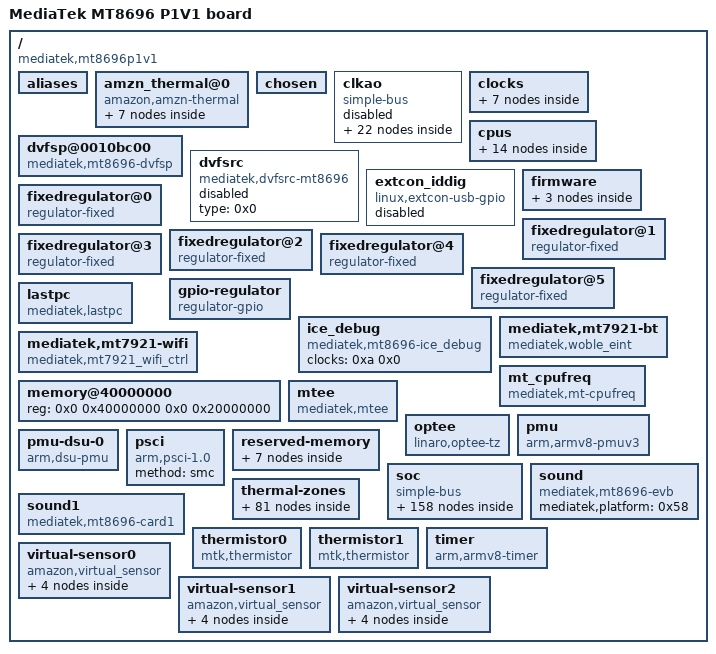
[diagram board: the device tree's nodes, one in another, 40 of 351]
/dts-v1/;

/ {
	#address-cells = <0x2>;
	#size-cells = <0x2>;
	compatible = "mediatek,mt8696p1v1", "mediatek,mt8696";
	interrupt-parent = <0x1>;
	model = "MediaTek MT8696 P1V1 board";

	__symbols__ {
		afe = "/soc/audio-controller@11228000";
		afe32 = "/soc/audio-controller@11220000";
		amzn_thermal = "/amzn_thermal@0";
		android = "/firmware/android";
		apmixedsys = "/soc/syscon@1000c000";
		atf_reserved_mem = "/reserved-memory/atf-reserved-memory@43000000";
		auxadc = "/soc/adc@11001000";
		board_trip10 = "/thermal-zones/top_thermal/trips/trip-point@0";
		board_trip11 = "/thermal-zones/top_thermal/trips/trip-point@1";
		board_trip12 = "/thermal-zones/top_thermal/trips/trip-point@2";
		board_trip_critical1 = "/thermal-zones/top_thermal/trips/trip-point@3";
		bottom_trip10 = "/thermal-zones/bottom_thermal/trips/trip-point@0";
		bottom_trip11 = "/thermal-zones/bottom_thermal/trips/trip-point@1";
		bottom_trip12 = "/thermal-zones/bottom_thermal/trips/trip-point@2";
		bottom_trip_critical1 = "/thermal-zones/bottom_thermal/trips/trip-point@3";
		clk12m = "/clocks/clk12m";
		clk13m = "/clocks/clk13m";
		clk26m = "/clocks/clk26m";
		clk32k = "/clocks/clk32k";
		clk_null = "/clocks/clk_null";
		clkao = "/clkao";
		clki2sin_mclk_i = "/clocks/oscillator@0";
		clksplin_mclk_i = "/clocks/oscillator@1";
		clovelly = "/soc/gpu@13000000";
		clusteroff = "/cpus/idle-states/clusteroff";
		cpu0 = "/cpus/cpu@000";
		cpu1 = "/cpus/cpu@001";
		cpu2 = "/cpus/cpu@002";
		cpu3 = "/cpus/cpu@003";
		cpu_cluster0 = "/amzn_thermal@0/cpu_core_cluster0";
		cpuoff = "/cpus/idle-states/cpuoff";
		cpus = "/cpus";
		disp_adl_ml = "/soc/disp_adl_ml@14013000";
		disp_befifo = "/soc/disp_befifo@1400f000";
		disp_fefifo = "/soc/disp_fefifo@14010000";
		disp_fmt = "/soc/disp_fmt@14001000";
		disp_hdr = "/soc/disp_hdr@14009000";
		disp_mix = "/soc/disp_mix@14014000";
		disp_osd = "/soc/disp_osd@14004000";
		disp_p2i = "/soc/disp_p2i@14002700";
		disp_r2r = "/soc/disp_r2r@15006000";
		disp_vdo = "/soc/disp_vdo@15001000";
		disp_vdout = "/soc/disp_vdout@14001000";
		disp_videoin = "/soc/disp_videoin@14002000";
		dispsys = "/soc/syscon@15000000";
		dramc = "/soc/dramc@10104000";
		dvfsp = "/dvfsp@0010bc00";
		dvfsrc = "/dvfsrc";
		earc_rx_codec = "/soc/earc-receiver@1a001000";
		eem_fsm = "/soc/eem_fsm@1100b000";
		emi = "/soc/emi@10203000";
		ether = "/soc/syscon@1101a000";
		ethernet = "/soc/ethernet@1101a000";
		extcon_usb = "/extcon_iddig";
		firmware = "/firmware";
		fstab = "/firmware/android/fstab";
		gce_mbox = "/soc/gce_mbox@10228000";
		gce_mbox_svp = "/soc/gce_mbox_svp@10228000";
		gic = "/soc/interrupt-controller@c000000";
		gpio_keys = "/soc/gpio_keys";
		hdmi_default = "/soc/pinctrl@1000b000/hdmi";
		hdmitx = "/soc/hdmitx@1a000000";
		i2c0 = "/soc/i2c@11007000";
		i2c1 = "/soc/i2c@11008000";
		i2c2 = "/soc/i2c@11009000";
		i2c3 = "/soc/i2c@11010000";
		i2c3_pins = "/soc/pinctrl@1000b000/i2c3";
		i2c4 = "/soc/i2c@10018000";
		i2c5 = "/soc/i2c@11011000";
		i2c5_pins = "/soc/pinctrl@1000b000/i2c5";
		ice = "/ice_debug";
		imgresz0 = "/soc/imgresz@1500c000";
		imgresz1 = "/soc/imgresz@1500c400";
		infrasys = "/soc/syscon@10001000";
		iommu = "/soc/m4u@10205000";
		iommu_sec = "/soc/m4u@1020e000";
		ion = "/soc/ion";
		ipsys = "/soc/syscon@10218000";
		irrx = "/soc/irrx@1000d000";
		irrx_pins_ir_input = "/soc/pinctrl@1000b000/irrx_pin_ir";
		irt_dma = "/soc/irt_dma@1500b000";
		larb0 = "/soc/larb@1400c000";
		larb1 = "/soc/larb@1602e000";
		larb3 = "/soc/larb@18002000";
		larb4 = "/soc/larb@1400e000";
		larb5 = "/soc/larb@15004000";
		larb6 = "/soc/larb@15005000";
		larb7 = "/soc/larb@1600d000";
		larb8 = "/soc/larb@14000000";
		lastpc = "/lastpc";
		ma5721_vsram_reg = "/soc/i2c@11010000/rt5738_buck@55";
		mcucfg = "/soc/syscon@c53a000";
		mcupm = "/soc/mcupm@c540000";
		mcusysoff = "/cpus/idle-states/mcusysoff";
		mfg = "/soc/mfg@13fbf000";
		mfg_2d = "/soc/mfg_2d";
		mfg_3d = "/soc/mfg_3d";
		mfg_async = "/soc/mfg_async";
		mfgcfg = "/soc/syscon@13fbf000";
		mmc0 = "/soc/mmc@11230000";
		mmc0_pins_default = "/soc/pinctrl@1000b000/mmc0default";
		mmc0_pins_uhs = "/soc/pinctrl@1000b000/mmc0";
		mmc1 = "/soc/mmc@11240000";
		mmc2 = "/soc/sdio@11250000";
		mmc2_fixed_pmu = "/fixedregulator@3";
		mmc2_fixed_pwr = "/fixedregulator@2";
		mmc2_pins_dat1 = "/soc/pinctrl@1000b000/sdio_dat1";
		mmc2_pins_default = "/soc/pinctrl@1000b000/mmc2default";
		mmc2_pins_eint = "/soc/pinctrl@1000b000/dat1_eint";
		mmc2_pins_low = "/soc/pinctrl@1000b000/sdio_low";
		mmc2_pins_uhs = "/soc/pinctrl@1000b000/mmc2";
		mmc_fixed_1v8_io = "/fixedregulator@1";
		mmc_fixed_3v3 = "/fixedregulator@0";
		mmsys = "/soc/syscon@14000000";
		mp2152_vgpu = "/gpio-regulator";
		mt6395 = "/soc/i2c@11010000/mt6395@62";
		mt6395_avdd2 = "/soc/i2c@11010000/mt6395@62/mt6395_buck2";
		mt6395_ldo1 = "/soc/i2c@11010000/mt6395@62/mt6395_ldo1";
		mt6395_vio18 = "/soc/i2c@11010000/mt6395@62/mt6395_buck3";
		mt6395_vio33 = "/soc/i2c@11010000/mt6395@62/mt6395_buck4";
		mt6395_vproc = "/soc/i2c@11010000/mt6395@62/mt6395_buck1";
		mt_cpufreq = "/mt_cpufreq";
		mtkfb = "/soc/mtkfb";
		nandc = "/soc/nfi@1100e000";
		nna_top_ports_wrapper_0 = "/soc/nna_top_ports_wrapper@10216000";
		optee_reserved_mem = "/reserved-memory/optee-reserved-memory@83040000";
		perisys = "/soc/syscon@10003000";
		pio = "/soc/pinctrl@1000b000";
		pmic_pins_eint = "/soc/pinctrl@1000b000/pmic_pins_eint";
		reserved_memory = "/reserved-memory";
		rng = "/soc/rng@1020f000";
		scpsys = "/soc/syscon@10006000";
		side_trip10 = "/thermal-zones/side_thermal/trips/trip-point@0";
		side_trip11 = "/thermal-zones/side_thermal/trips/trip-point@1";
		side_trip12 = "/thermal-zones/side_thermal/trips/trip-point@2";
		side_trip_critical1 = "/thermal-zones/side_thermal/trips/trip-point@3";
		smi_common = "/soc/smi@1400d000";
		soc_data = "/soc/soc_data@8000000";
		soc_trip10 = "/thermal-zones/soc_thermal/trips/trip-point@0";
		soc_trip11 = "/thermal-zones/soc_thermal/trips/trip-point@1";
		soc_trip12 = "/thermal-zones/soc_thermal/trips/trip-point@2";
		soc_trip13 = "/thermal-zones/soc_thermal/trips/trip-point@3";
		soc_trip_critical1 = "/thermal-zones/soc_thermal/trips/trip-point@4";
		sound = "/sound";
		sound1 = "/sound1";
		spi0 = "/soc/spi@1100a000";
		spi2 = "/soc/spi@11015000";
		ssusb = "/soc/usb@11201000";
		stc = "/soc/stc@10008000";
		syscfg_pctl_0 = "/soc/syscfg_pctl_0@11c30000";
		syscfg_pctl_1 = "/soc/syscfg_pctl_1@11d00000";
		syscfg_pctl_2 = "/soc/syscfg_pctl_2@11d20000";
		syscfg_pctl_3 = "/soc/syscfg_pctl_3@11e10000";
		syscfg_pctl_4 = "/soc/syscfg_pctl_4@11f40000";
		syscfg_pctl_a = "/soc/syscfg_pctl_a@10005000";
		systracker = "/soc/systracker@10208000";
		tboard_thermistor = "/soc/thermal-sensor";
		thermal = "/soc/thermal@1100b800";
		thermistor0 = "/thermistor0";
		thermistor1 = "/thermistor1";
		timer = "/timer";
		tmp103a = "/soc/i2c@11011000/tmp103@70";
		tmp103c = "/soc/i2c@11011000/tmp103@72";
		topckgen = "/soc/syscon@10000000";
		toprgu = "/soc/toprgu@10007000";
		u2port0 = "/soc/usb-phy@11c20000/usb-phy@11c20000";
		u2port1 = "/soc/usb-phy@11c20000/usb-phy@11c21000";
		u2port2 = "/soc/usb-phy@11c20000/usb-phy@11c22000";
		u3phy0 = "/soc/usb-phy@11c20000";
		u3port0 = "/soc/usb-phy@11c20000/usb-phy@11c20700";
		uart0 = "/soc/serial@11002000";
		uart1 = "/soc/serial@11002400";
		uart2 = "/soc/serial@10049000";
		usb_host0 = "/soc/usb@11201000/xhci@11200000";
		usb_vbus_3v3 = "/fixedregulator@5";
		usb_vbus_5v0 = "/fixedregulator@4";
		vcu = "/soc/vcu@16000000";
		vdec = "/soc/vdec@16020000";
		vdec_gcon = "/soc/vdec_gcon@1602f000";
		vdec_soc_gcon = "/soc/vdec_soc_gcon@1600f000";
		venc = "/soc/syscon@18000000";
		virtual_sensor0 = "/virtual-sensor0";
		virtual_sensor1 = "/virtual-sensor1";
		virtual_sensor2 = "/virtual-sensor2";
		vq = "/soc/vq@14000000";
		wifi_cool = "/amzn_thermal@0/wifi_cool";
	};

	aliases {
		i2c0 = "/soc/i2c@11007000";
		i2c1 = "/soc/i2c@11008000";
		i2c2 = "/soc/i2c@11009000";
		i2c3 = "/soc/i2c@11010000";
		i2c4 = "/soc/i2c@10018000";
		i2c5 = "/soc/i2c@11011000";
	};

	amzn_thermal@0 {
		compatible = "amazon,amzn-thermal";
		phandle = <0xba>;

		cooling_devices {

			cpucore_cool_cluster0 {
				cluster_id = <0x0>;
				device_type = "cpucore";
				dyn_coeff = <0x0>;
				min_state = <0x1>;
				node_name = "cpu_core_cluster0";
			};

			cpufreq_cool_cluster0 {
				cluster_id = <0x0>;
				device_type = "cpufreq";
				dyn_coeff = <0x8c>;
				min_state = <0xf4240>;
				node_name = "cpus";
			};

			gpufreq_cool {
				cluster_id = <0x0>;
				device_type = "gpufreq";
				dyn_coeff = <0x1b5>;
				min_state = <0x190>;
				node_name = "gpu";
			};

			wifi_cool_device {
				device_type = "wifi";
				min_state = <0x0>;
				node_name = "wifi_cool";
			};
		};

		cpu_core_cluster0 {
			#cooling-cells = <0x2>;
			phandle = <0x48>;
		};

		wifi_cool {
			#cooling-cells = <0x2>;
			phandle = <0x49>;
		};
	};

	chosen {
		bootargs = "console=tty0 console=ttyS1,921600n1 earlycon=uart8250,mmio32,0x11002400 root=/dev/ram initrd=0x44000000,0x600000 loglevel=8 initcall_debug=1 androidboot.hardware=mt8696 androidboot.selinux=permissive";
	};

	clkao {
		compatible = "simple-bus";
		phandle = <0xab>;
		status = "disabled";

		bring-up {
			clock-names = "0", "1", "2", "3", "4", "5", "6", "7", "8", "9", "10", "11", "12", "13", "14", "15", "16", "17", "18", "19", "20", "21", "22", "23", "24", "25", "26", "27", "28", "29", "30", "31", "32", "33", "34", "35", "36", "37", "38", "39", "40", "41", "42", "43", "44", "45", "46", "47", "48", "49", "50", "51", "52", "53", "54", "55", "56", "57", "58", "59", "60", "61", "62", "63", "64", "65", "66", "67", "68", "69", "70", "71", "72", "73", "74", "75", "76", "77", "78", "79", "80", "81", "82", "83", "84", "85", "86", "87", "88", "89", "90", "91", "92", "93", "94", "95", "96", "97", "98", "99", "100", "101", "102", "103", "104", "105", "106", "107", "108", "109", "110", "111", "112", "113", "114", "115", "116", "117", "118", "119", "120", "121", "122", "123", "124", "125", "126", "127", "128", "129", "130", "131", "132", "133", "134", "135", "136", "137", "138", "139", "140", "141", "142", "143", "144", "145", "146", "147", "148", "149", "150", "151", "152", "153", "154", "155", "156", "157", "158", "159", "160", "161", "162", "163", "164", "165", "166", "167", "168", "169", "170", "171", "172", "173", "174", "175", "176", "177", "178", "179", "180", "181", "182", "183", "184", "185", "186", "187", "188", "189", "190", "191", "192", "193", "194", "195", "196", "197", "198", "199", "200", "201", "202", "203", "204", "205", "206", "207", "208", "209", "210", "211", "212", "213", "214", "215", "216", "217", "218", "219", "220", "221", "222", "223", "224", "225", "226", "227", "228", "229", "230", "231", "232", "233", "234", "235", "236", "237", "238", "239", "240", "241", "242";
			clocks = <0x22 0x0 0x22 0x1 0x22 0x2 0x22 0x3 0x22 0x4 0x22 0x5 0x22 0x6 0x22 0x7 0x22 0x8 0x22 0x9 0x22 0xa 0x22 0xb 0x22 0xc 0x22 0xd 0x22 0xe 0x22 0xf 0x22 0x10 0x9 0x65 0x9 0x66 0x9 0x67 0x9 0x68 0x9 0x69 0x9 0x6a 0x9 0x6b 0x9 0x6c 0x9 0x6d 0x9 0x6e 0x9 0x6f 0x9 0x70 0x9 0x71 0x9 0x72 0x9 0x73 0x9 0x74 0x9 0x75 0x9 0x76 0x9 0x77 0x9 0x78 0x9 0x79 0x9 0x7a 0x9 0x7b 0x9 0x7c 0x9 0x7d 0x9 0x7e 0x9 0x7f 0x9 0x80 0x9 0x81 0x9 0x82 0x9 0x83 0x9 0x84 0x9 0x85 0x9 0x86 0x9 0x87 0x9 0x88 0x9 0x89 0x9 0x8a 0x9 0x8b 0x9 0x8c 0x9 0x8d 0x9 0x8e 0x9 0x8f 0x9 0x90 0x9 0x91 0x9 0x92 0x9 0x93 0x9 0x94 0x9 0x95 0x9 0x96 0x9 0x97 0x9 0x98 0x9 0x99 0x9 0x9a 0x9 0x9b 0x9 0x9c 0x9 0x9d 0x9 0x9e 0x9 0x9f 0x9 0xa0 0x9 0xa1 0x9 0xa2 0x9 0xa3 0x9 0xa4 0x9 0xa5 0x9 0xa6 0x9 0xa7 0x9 0xa8 0x9 0xa9 0x9 0xaa 0x9 0xab 0x9 0xac 0x9 0xad 0x9 0xae 0x9 0xaf 0x9 0xb0 0x9 0xb1 0x9 0xb2 0x9 0xb3 0x9 0xb4 0x9 0xb5 0x9 0xb6 0x9 0xb7 0x9 0xb8 0x9 0xb9 0x9 0xba 0x9 0xbb 0x9 0xbc 0x9 0xbd 0x9 0xbe 0x9 0xbf 0x9 0xc0 0x9 0xc1 0x9 0xc2 0x9 0xc3 0x9 0xc4 0x9 0xc5 0x9 0xc6 0x9 0xc7 0xa 0x0 0xa 0x1 0xa 0x2 0xa 0x3 0xa 0x4 0xa 0x5 0xa 0x6 0xa 0x7 0xa 0x8 0xa 0x9 0xa 0xa 0xa 0xb 0xa 0xc 0xa 0xd 0xa 0xf 0x14 0x0 0x14 0x1 0x14 0x2 0x14 0x3 0x14 0x4 0x14 0x5 0x14 0x6 0x14 0x7 0x14 0x8 0x14 0x9 0x14 0xa 0x14 0xb 0x14 0xc 0x14 0xd 0x14 0xe 0x14 0xf 0x14 0x10 0x14 0x11 0x14 0x12 0x14 0x13 0x14 0x14 0x14 0x15 0x14 0x16 0x14 0x17 0x14 0x18 0x14 0x19 0x14 0x1a 0x14 0x1b 0x14 0x1c 0x14 0x1d 0x14 0x1e 0x14 0x1f 0x14 0x20 0x1d 0x0 0x1d 0x1 0x1d 0x2 0x27 0x0 0x27 0x1 0x27 0x2 0x27 0x3 0x27 0x4 0x27 0x5 0x27 0x6 0x27 0x7 0x3a 0x0 0x3a 0x1 0x3a 0x2 0x3a 0x3 0x3a 0x4 0x3a 0x5 0x3a 0x6 0x3a 0x7 0x3a 0x8 0x3a 0x9 0x3a 0xa 0x3a 0xb 0x3a 0xc 0x3a 0xd 0x3a 0xe 0x3a 0xf 0x3a 0x10 0x3a 0x11 0x3a 0x12 0x3a 0x13 0x3a 0x14 0x3a 0x15 0x3a 0x16 0x3a 0x17 0x3a 0x18 0x3a 0x19 0x3a 0x1a 0x3a 0x1b 0x3a 0x1c 0x3a 0x1d 0x3a 0x1e 0x3a 0x1f 0x3a 0x20 0x3a 0x21 0x3b 0x0 0x3b 0x1 0x3b 0x2 0x3b 0x3 0x3b 0x4 0x3b 0x5 0x3b 0x6 0x3b 0x7 0x3b 0x8 0x3b 0x9 0x3b 0xa 0x3b 0xb 0x3b 0xc 0x3b 0xd 0x3b 0xe 0x3b 0xf 0x3b 0x10 0x3b 0x11 0x3b 0x12 0x3b 0x13 0x3b 0x14 0x3e 0x0 0x3e 0x1 0x3e 0x2 0x3e 0x3 0x3e 0x4 0x3f 0x0 0x3f 0x1 0x3f 0x2 0x3f 0x3 0x3f 0x4 0x40 0x0 0x40 0x1>;
			compatible = "mediatek,clk-bring-up";
		};

		bring-up-pd-audasrc {
			compatible = "mediatek,scpsys-bring-up";
			power-domains = <0x1e 0xc>;
		};

		bring-up-pd-audio {
			compatible = "mediatek,scpsys-bring-up";
			power-domains = <0x1e 0xb>;
		};

		bring-up-pd-dispcommon {
			compatible = "mediatek,scpsys-bring-up";
			power-domains = <0x1e 0x9>;
		};

		bring-up-pd-dispmain {
			compatible = "mediatek,scpsys-bring-up";
			power-domains = <0x1e 0x7>;
		};

		bring-up-pd-dispsub {
			compatible = "mediatek,scpsys-bring-up";
			power-domains = <0x1e 0x8>;
		};

		bring-up-pd-ether {
			compatible = "mediatek,scpsys-bring-up";
			power-domains = <0x1e 0xe>;
		};

		bring-up-pd-hdmirx {
			compatible = "mediatek,scpsys-bring-up";
			power-domains = <0x1e 0x6>;
		};

		bring-up-pd-hdmirxphy {
			compatible = "mediatek,scpsys-bring-up";
			power-domains = <0x1e 0x13>;
		};

		bring-up-pd-hdmitx {
			compatible = "mediatek,scpsys-bring-up";
			power-domains = <0x1e 0x5>;
		};

		bring-up-pd-mfg {
			compatible = "mediatek,scpsys-bring-up";
			power-domains = <0x1e 0x10>;
		};

		bring-up-pd-mfg2 {
			compatible = "mediatek,scpsys-bring-up";
			power-domains = <0x1e 0x11>;
		};

		bring-up-pd-mfg3 {
			compatible = "mediatek,scpsys-bring-up";
			power-domains = <0x1e 0x12>;
		};

		bring-up-pd-mmcommon {
			compatible = "mediatek,scpsys-bring-up";
			power-domains = <0x1e 0x3>;
		};

		bring-up-pd-mmcu {
			compatible = "mediatek,scpsys-bring-up";
			power-domains = <0x1e 0xa>;
		};

		bring-up-pd-mmtop {
			compatible = "mediatek,scpsys-bring-up";
			power-domains = <0x1e 0x2>;
		};

		bring-up-pd-nna0 {
			compatible = "mediatek,scpsys-bring-up";
			power-domains = <0x1e 0xf>;
		};

		bring-up-pd-osd {
			compatible = "mediatek,scpsys-bring-up";
			power-domains = <0x1e 0x4>;
		};

		bring-up-pd-ssusb {
			compatible = "mediatek,scpsys-bring-up";
			power-domains = <0x1e 0xd>;
		};

		bring-up-pd-vdecore0 {
			compatible = "mediatek,scpsys-bring-up";
			power-domains = <0x1e 0x0>;
		};

		bring-up-pd-vdecsoc {
			compatible = "mediatek,scpsys-bring-up";
			power-domains = <0x1e 0x14>;
		};

		bring-up-pd-venc {
			compatible = "mediatek,scpsys-bring-up";
			power-domains = <0x1e 0x1>;
		};
	};

	clocks {

		clk12m {
			#clock-cells = <0x0>;
			clock-frequency = <0xb71b00>;
			compatible = "fixed-clock";
			phandle = <0x5c>;
		};

		clk13m {
			#clock-cells = <0x0>;
			clock-frequency = <0xc65d40>;
			compatible = "fixed-clock";
			phandle = <0x13>;
		};

		clk26m {
			#clock-cells = <0x0>;
			clock-frequency = <0x18cba80>;
			clock-output-names = "clk26m";
			compatible = "fixed-clock";
			phandle = <0x20>;
		};

		clk32k {
			#clock-cells = <0x0>;
			clock-frequency = <0x8000>;
			clock-output-names = "clk32k";
			compatible = "fixed-clock";
			phandle = <0x5d>;
		};

		clk_null {
			#clock-cells = <0x0>;
			clock-frequency = <0x0>;
			compatible = "fixed-clock";
			phandle = <0x5b>;
		};

		oscillator@0 {
			#clock-cells = <0x0>;
			clock-frequency = <0x2ee0000>;
			clock-output-names = "i2si0_mck_i";
			compatible = "fixed-clock";
			phandle = <0x5e>;
		};

		oscillator@1 {
			#clock-cells = <0x0>;
			clock-frequency = <0x2ee0000>;
			clock-output-names = "splin_mck_i";
			compatible = "fixed-clock";
			phandle = <0x5f>;
		};
	};

	cpus {
		#address-cells = <0x1>;
		#cooling-cells = <0x2>;
		#size-cells = <0x0>;
		phandle = <0x45>;

		cpu-map {

			cluster0 {

				core0 {
					cpu = <0x5>;
				};

				core1 {
					cpu = <0x6>;
				};

				core2 {
					cpu = <0x7>;
				};

				core3 {
					cpu = <0x8>;
				};
			};
		};

		cpu@000 {
			clock-frequency = <0x6553f100>;
			compatible = "arm,cortex-a55";
			cpu-idle-states = <0x2 0x3 0x4>;
			device_type = "cpu";
			enable-method = "psci";
			phandle = <0x5>;
			reg = <0x0>;
		};

		cpu@001 {
			clock-frequency = <0x6553f100>;
			compatible = "arm,cortex-a55";
			cpu-idle-states = <0x2 0x3 0x4>;
			device_type = "cpu";
			enable-method = "psci";
			phandle = <0x6>;
			reg = <0x100>;
		};

		cpu@002 {
			clock-frequency = <0x6553f100>;
			compatible = "arm,cortex-a55";
			cpu-idle-states = <0x2 0x3 0x4>;
			device_type = "cpu";
			enable-method = "psci";
			phandle = <0x7>;
			reg = <0x200>;
		};

		cpu@003 {
			clock-frequency = <0x6553f100>;
			compatible = "arm,cortex-a55";
			cpu-idle-states = <0x2 0x3 0x4>;
			device_type = "cpu";
			enable-method = "psci";
			phandle = <0x8>;
			reg = <0x300>;
		};

		idle-states {
			entry-method = "psci";

			clusteroff {
				arm,psci-suspend-param = <0x1010001>;
				compatible = "arm,idle-state";
				entry-latency-us = <0x64>;
				exit-latency-us = <0x15e>;
				local-timer-stop;
				min-residency-us = <0x834>;
				phandle = <0x3>;
			};

			cpuoff {
				arm,psci-suspend-param = <0x10001>;
				compatible = "arm,idle-state";
				entry-latency-us = <0x64>;
				exit-latency-us = <0xfa>;
				local-timer-stop;
				min-residency-us = <0x640>;
				phandle = <0x2>;
			};

			mcusysoff {
				arm,psci-suspend-param = <0x1010002>;
				compatible = "arm,idle-state";
				entry-latency-us = <0x12c>;
				exit-latency-us = <0x4b0>;
				local-timer-stop;
				min-residency-us = <0xa28>;
				phandle = <0x4>;
			};
		};
	};

	dvfsp@0010bc00 {
		CCI-table = <0x578 0x60 0x2 0x1 0x549 0x5c 0x2 0x1 0x51a 0x58 0x2 0x1 0x4ec 0x54 0x2 0x1 0x4a6 0x4e 0x2 0x1 0x483 0x4b 0x2 0x1 0x460 0x47 0x2 0x1 0x3d8 0x40 0x2 0x1 0x395 0x3e 0x2 0x1 0x33b 0x3a 0x2 0x1 0x2e1 0x36 0x2 0x2 0x29d 0x33 0x2 0x2 0x243 0x2f 0x2 0x2 0x200 0x2c 0x2 0x2 0x1bd 0x29 0x2 0x2 0x190 0x26 0x2 0x2>;
		L-table = <0x7d0 0x60 0x1 0x1 0x78d 0x5c 0x1 0x1 0x74a 0x58 0x1 0x1 0x708 0x53 0x1 0x1 0x6c5 0x50 0x1 0x1 0x682 0x4b 0x1 0x1 0x60c 0x47 0x1 0x1 0x5c3 0x42 0x2 0x1 0x55f 0x40 0x2 0x1 0x4fb 0x3a 0x2 0x1 0x497 0x36 0x2 0x1 0x433 0x31 0x2 0x1 0x3e7 0x2e 0x2 0x1 0x39d 0x2b 0x2 0x1 0x352 0x28 0x2 0x1 0x306 0x26 0x2 0x1>;
		brd-gpios = <0x24 0x15 0x0 0x24 0x14 0x0 0x24 0x13 0x0>;
		change_flag = <0x0>;
		compatible = "mediatek,mt8696-dvfsp";
		little-down-time = <0x2ee>;
		little-rise-time = <0x3e8>;
		phandle = <0xac>;
		reg = <0x0 0x10bc00 0x0 0x1400>;
		state = <0x1>;
		vsram = <0x1>;
	};

	dvfsrc {
		compatible = "mediatek,dvfsrc-mt8696";
		phandle = <0xaf>;
		status = "disabled";
		type = <0x0>;
	};

	extcon_iddig {
		compatible = "linux,extcon-usb-gpio";
		phandle = <0xb5>;
		status = "disabled";
	};

	firmware {
		phandle = <0x60>;

		android {
			compatible = "android,firmware";
			phandle = <0x61>;

			fstab {
				compatible = "android,fstab";
				phandle = <0x62>;

				vendor {
					compatible = "android,vendor";
					dev = "/dev/block/platform/soc/11230000.mmc/by-name/vendor";
					fsmgr_flags = "wait,verify";
					mnt_flags = "ro";
					type = "ext4";
				};
			};
		};
	};

	fixedregulator@0 {
		compatible = "regulator-fixed";
		enable-active-high;
		phandle = <0x30>;
		regulator-max-microvolt = <0x325aa0>;
		regulator-min-microvolt = <0x325aa0>;
		regulator-name = "mmc_power";
	};

	fixedregulator@1 {
		compatible = "regulator-fixed";
		enable-active-high;
		phandle = <0x31>;
		regulator-max-microvolt = <0x1b7740>;
		regulator-min-microvolt = <0x1b7740>;
		regulator-name = "mmc_io";
	};

	fixedregulator@2 {
		compatible = "regulator-fixed";
		enable-active-high;
		phandle = <0x37>;
		regulator-always-on;
		regulator-max-microvolt = <0x325aa0>;
		regulator-min-microvolt = <0x325aa0>;
		regulator-name = "sdio_power";
	};

	fixedregulator@3 {
		compatible = "regulator-fixed";
		enable-active-high;
		gpio = <0x24 0x1a 0x0>;
		phandle = <0x38>;
		regulator-max-microvolt = <0x1b7740>;
		regulator-min-microvolt = <0x1b7740>;
		regulator-name = "sdio_pmu";
		startup-delay-us = <0x30d40>;
	};

	fixedregulator@4 {
		compatible = "regulator-fixed";
		phandle = <0x2d>;
		regulator-always-on;
		regulator-max-microvolt = <0x4c4b40>;
		regulator-min-microvolt = <0x4c4b40>;
		regulator-name = "vbus";
		regulator-type = "voltage";
	};

	fixedregulator@5 {
		compatible = "regulator-fixed";
		phandle = <0x2c>;
		regulator-always-on;
		regulator-max-microvolt = <0x325aa0>;
		regulator-min-microvolt = <0x325aa0>;
		regulator-name = "usb vbus";
	};

	gpio-regulator {
		compatible = "regulator-gpio";
		enable-active-high;
		enable-gpio = <0x24 0x2 0x0>;
		gpios = <0x24 0x1c 0x0>;
		phandle = <0xb>;
		regulator-max-microvolt = <0xdbba0>;
		regulator-min-microvolt = <0xc3500>;
		regulator-name = "mp2152_vgpu";
		startup-delay-us = <0x1388>;
		states = <0xc3500 0x0 0xdbba0 0x1>;
	};

	ice_debug {
		clock-names = "ice_dbg";
		clocks = <0xa 0x0>;
		compatible = "mediatek,mt8696-ice_debug", "mediatek,mt2701-ice_debug";
		phandle = <0xb0>;
	};

	lastpc {
		compatible = "mediatek,lastpc";
		phandle = <0xad>;
	};

	mediatek,mt7921-bt {
		compatible = "mediatek,woble_eint";
		interrupt-parent = <0x24>;
		interrupts = <0xc 0x8 0x1 0x0>;
		status = "okay";
	};

	mediatek,mt7921-wifi {
		compatible = "mediatek,mt7921_wifi_ctrl";
		interrupt-parent = <0x24>;
		interrupts = <0x0 0x8>;
		status = "okay";
	};

	memory@40000000 {
		device_type = "memory";
		reg = <0x0 0x40000000 0x0 0x20000000>;
	};

	mt_cpufreq {
		compatible = "mediatek,mt-cpufreq";
		phandle = <0xae>;
	};

	mtee {
		compatible = "mediatek,mtee";
	};

	optee {
		clock-names = "GCPU_B", "ECC";
		clocks = <0x9 0x9f 0x9 0xa0>;
		compatible = "linaro,optee-tz";
		method = "smc";
	};

	pmu {
		compatible = "arm,armv8-pmuv3", "arm,cortex-a7-pmu";
		interrupt-parent = <0x1>;
		interrupts = <0x1 0x7 0x4>;
	};

	pmu-dsu-0 {
		compatible = "arm,dsu-pmu";
		cpus = <0x5 0x6 0x7 0x8>;
		interrupts = <0x0 0x12 0x4>;
	};

	psci {
		compatible = "arm,psci-1.0";
		method = "smc";
	};

	reserved-memory {
		#address-cells = <0x2>;
		#size-cells = <0x2>;
		phandle = <0x63>;
		ranges;

		atf-reserved-memory@43000000 {
			compatible = "mediatek,mt8696-atf-reserved-memory";
			no-map;
			phandle = <0x64>;
			reg = <0x0 0x43000000 0x0 0x40000>;
		};

		atf_aee_log_reserved_mem@57240000 {
			compatible = "mediatek,mt8696-atf-aee-log";
			no-map;
			reg = <0x0 0x57240000 0x0 0x4000>;
		};

		minirdump-reserved-memory@594f0000 {
			compatible = "mediatek,minirdump";
			reg = <0x0 0x594f0000 0x0 0x10000>;
		};

		optee-reserved-memory@83040000 {
			compatible = "mediatek,mt8696-optee-reserved-memory";
			no-map;
			phandle = <0x65>;
			reg = <0x0 0x83040000 0x0 0x14200000>;
		};

		pstore-reserved-memory@59410000 {
			compatible = "mediatek,pstore";
			reg = <0x0 0x59410000 0x0 0xe0000>;
		};

		ram_console-reserved-memory@59400000 {
			compatible = "mediatek,ram_console";
			reg = <0x0 0x59400000 0x0 0x10000>;
		};

		reserve-memory-mcupm_share {
			alignment = <0x0 0x10000>;
			alloc-ranges = <0x0 0x40000000 0x0 0x60000000>;
			compatible = "mediatek,reserve-memory-mcupm_share";
			no-map;
			size = <0x0 0x610000>;
			status = "okay";
		};
	};

	soc {
		#address-cells = <0x2>;
		#size-cells = <0x2>;
		compatible = "simple-bus";
		ranges;

		adc@11001000 {
			#io-channel-cells = <0x1>;
			clock-names = "main";
			clocks = <0x14 0x12>;
			compatible = "mediatek,mt8696-auxadc", "mediatek,mt8173-auxadc";
			phandle = <0x21>;
			reg = <0x0 0x11001000 0x0 0x1000>;
			status = "okay";
		};

		audio-controller@11220000 {
			assigned-clock-parents = <0x9 0x27 0x9 0x2c 0x9 0x31 0x9 0x36 0x9 0x3b 0x9 0x19 0x9 0x19 0x9 0x19>;
			assigned-clocks = <0x9 0x7c 0x9 0x7d 0x9 0x7e 0x9 0x7f 0x9 0x80 0x9 0x86 0x9 0x87 0x9 0x88>;
			clock-names = "audio_26msel", "audio_sel", "aud_intbussel", "infra_ipsys", "a1syshp_sel", "intdir_sel", "a2syshp_sel", "a3syshp_sel", "a4syshp_sel", "apll3_d4", "apll4_d4", "apll5_d4", "hdmirx_apll_d6", "apll_sel", "apll2_sel", "apll3_sel", "apll4_sel", "apll5_sel", "apll1_d8", "apll2_d8", "apll3_d8", "apll4_d8", "apll5_d8", "asml_sel", "asmm_sel", "asmh_sel", "apll12_div4", "apll12_div0", "apll12_div1", "apll12_div2", "apll12_div3", "hf_faud_iec_ck", "hf_fi2si1_m_ck", "hf_fi2si2_m_ck", "hf_fi2so1_m_ck", "hf_fi2so2_m_ck", "i2si1_sel", "i2si2_sel", "i2so1_sel", "i2so2_sel", "apll1", "apll2", "apll3", "apll4", "apll5";
			clocks = <0x9 0x7a 0x9 0x79 0x9 0x7b 0xa 0xd 0x9 0x82 0x9 0x78 0x9 0x83 0x9 0x84 0x9 0x85 0x9 0x30 0x9 0x35 0x9 0x3a 0x9 0x43 0x9 0x7c 0x9 0x7d 0x9 0x7e 0x9 0x7f 0x9 0x80 0x9 0x27 0x9 0x2c 0x9 0x31 0x9 0x36 0x9 0x3b 0x9 0x86 0x9 0x87 0x9 0x88 0x9 0xb9 0x9 0xb5 0x9 0xb6 0x9 0xb7 0x9 0xb8 0x9 0xb4 0x9 0xb0 0x9 0xb1 0x9 0xb2 0x9 0xb3 0x9 0x8c 0x9 0x8d 0x9 0x8a 0x9 0x8b 0x22 0x5 0x22 0x6 0x22 0x7 0x22 0x8 0x22 0x9>;
			compatible = "mediatek,mt8532-afe-pcm";
			interrupts = <0x0 0x137 0x4>;
			mediatek,etdm-in-data-modes = <0x0 0x1 0x0>;
			mediatek,etdm-out-data-modes = <0x1 0x1 0x1>;
			mediatek,scpsys-regmap = <0x1e>;
			mediatek,spdif-in-arc-mux = <0x2>;
			mediatek,topckgen-regmap = <0x9>;
			phandle = <0x59>;
			power-domains = <0x1e 0xb>;
			reg = <0x0 0x11220000 0x0 0x6000 0x0 0x11210000 0x0 0x10000>;
			status = "okay";
		};

		audio-controller@11228000 {
			assigned-clock-parents = <0x22 0x5 0x22 0x6 0x9 0x26 0x9 0x2b>;
			assigned-clocks = <0x9 0x7c 0x9 0x7d 0x9 0x82 0x9 0x83>;
			clock-names = "apll1", "apll2", "infra_audio", "apll1_d2", "apll1_d4", "apll1_d8", "apll1_d16", "apll2_d2", "apll2_d4", "apll2_d8", "apll2_d16", "audio_sel", "audio_26msel", "aud_intbussel", "apll_sel", "apll2_sel", "a1syshp_sel", "a2syshp_sel", "apll12_div0", "apll12_div2", "apll12_div3", "i2so1_sel", "i2so2_sel", "i2si1_sel";
			clocks = <0x22 0x5 0x22 0x6 0xa 0x1 0x9 0x25 0x9 0x26 0x9 0x27 0x9 0x28 0x9 0x2a 0x9 0x2b 0x9 0x2c 0x9 0x2d 0x9 0x79 0x9 0x7a 0x9 0x7b 0x9 0x7c 0x9 0x7d 0x9 0x82 0x9 0x83 0x9 0xb5 0x9 0xb7 0x9 0xb8 0x9 0x8a 0x9 0x8b 0x9 0x8c>;
			compatible = "mediatek,mt8696-afe-pcm";
			interrupts = <0x0 0x10b 0x4>;
			mediatek,etdm-clock-modes = <0x0 0x1>;
			mediatek,etdm-in-data-modes = <0x1 0x1>;
			mediatek,etdm-out-data-modes = <0x1 0x1>;
			mediatek,hdmi-clk-force-on = <0x1>;
			mediatek,scpsys-regmap = <0x1e>;
			mediatek,topckgen-regmap = <0x9>;
			phandle = <0x58>;
			reg = <0x0 0x11228000 0x0 0x4000>;
			status = "okay";
		};

		cmdq-test {
			compatible = "mediatek,cmdq-test";
			mboxes = <0x1f 0x17 0xffffffff 0x1 0x1f 0x16 0xffffffff 0x1 0x42 0xc 0xffffffff 0x1>;
			mediatek,gce = <0x1f>;
			token_gpr_set4 = [02 c0];
			token_user0 = [01 97];
		};

		disp_adl_ml@14013000 {
			compatible = "mediatek,mt8696-adl-ml";
			interrupts = <0x0 0xde 0x4>;
			phandle = <0x9c>;
			reg = <0x0 0x14013000 0x0 0x1000 0x0 0x15013000 0x0 0x1000>;
		};

		disp_befifo@1400f000 {
			compatible = "mediatek,mt8696-befifo";
			interrupts = <0x0 0xde 0x4>;
			phandle = <0x9a>;
			reg = <0x0 0x1400f000 0x0 0x1000>;
		};

		disp_fefifo@14010000 {
			compatible = "mediatek,mt8696-fefifo";
			interrupts = <0x0 0xfc 0x4 0x0 0x118 0x4 0x0 0xd9 0x4 0x0 0xcf 0x4>;
			phandle = <0x9b>;
			reg = <0x0 0x14010000 0x0 0x1000 0x0 0x14011000 0x0 0x1000 0x0 0x15010000 0x0 0x1000 0x0 0x15017000 0x0 0x1000>;
		};

		disp_fmt@14001000 {
			compatible = "mediatek,mt8696-fmt";
			interrupts = <0x0 0xdf 0x4 0x0 0xe0 0x4 0x0 0xe1 0x4 0x0 0xe2 0x4 0x0 0xe3 0x4 0x0 0xe4 0x4 0x0 0xe5 0x4>;
			phandle = <0x94>;
			reg = <0x0 0x10000000 0x0 0x1000 0x0 0x14001000 0x0 0x400 0x0 0x15000000 0x0 0x100 0x0 0x15001000 0x0 0x100 0x0 0x15008000 0x0 0x100>;
		};

		disp_hdr@14009000 {
			compatible = "mediatek,mt8696-hdr";
			interrupts = <0x0 0xf8 0x4>;
			phandle = <0x99>;
			reg = <0x0 0x14009000 0x0 0x1000 0x0 0x1400a000 0x0 0x1000 0x0 0x1400b000 0x0 0x400 0x0 0x15012000 0x0 0x1000 0x0 0x15015000 0x0 0x1000 0x0 0x15016000 0x0 0x1000>;
		};

		disp_mix@14014000 {
			compatible = "mediatek,mt8696-dispmix";
			phandle = <0x9d>;
			reg = <0x0 0x14014000 0x0 0x200>;
		};

		disp_osd@14004000 {
			compatible = "mediatek,mt8696-osd";
			gce-event-names = "OSD3_FRAME_END_IRQ_B";
			gce-events = <0x1f 0x33>;
			interrupts = <0x0 0xd7 0x4>;
			mboxes = <0x1f 0x4 0xffffffff 0x1 0x1f 0x5 0xffffffff 0x4>;
			phandle = <0x98>;
			reg = <0x0 0x14004000 0x0 0x300 0x0 0x14003000 0x0 0x300 0x0 0x1400cf80 0x0 0x80 0x0 0x1400ef80 0x0 0x80>;
		};

		disp_p2i@14002700 {
			compatible = "mediatek,mt8696-p2i";
			phandle = <0x97>;
			reg = <0x0 0x14002700 0x0 0x100>;
		};

		disp_r2r@15006000 {
			compatible = "mediatek,mt8696-r2r";
			interrupts = <0x0 0xfb 0x4>;
			phandle = <0x9f>;
			reg = <0x0 0x15006000 0x0 0x1000>;
		};

		disp_vdo@15001000 {
			#interrupts = <0x0 0xf8 0x4>;
			compatible = "mediatek,mt8696-vdo";
			phandle = <0x9e>;
			reg = <0x0 0x15001000 0x0 0x1000 0x0 0x15008000 0x0 0x1000>;
		};

		disp_vdout@14001000 {
			compatible = "mediatek,mt8696-vdout";
			phandle = <0x95>;
			reg = <0x0 0x14001000 0x0 0xd00>;
		};

		disp_videoin@14002000 {
			compatible = "mediatek,mt8696-videoin";
			phandle = <0x96>;
			reg = <0x0 0x14002000 0x0 0x100 0x0 0x1400e300 0x0 0x100>;
		};

		display-pm-disp-m {
			clock-names = "vdo3", "dispfmt3", "m_vdo_fe_fifo", "m_film_grain", "m_hdr_vdo_fe", "m_vdo_fe_adl", "r2r";
			clocks = <0x3b 0x0 0x3b 0x1 0x3b 0xe 0x3b 0xf 0x3b 0x10 0x3b 0x11 0x3b 0x2>;
			compatible = "mediatek,mt8696-disp-clk";
			mediatek,pm_type = <0x3>;
			power-domains = <0x1e 0x7>;
		};

		display-pm-disp-s {
			clock-names = "vdo4", "dispfmt4", "s_vdo_fe_fifo", "s_film_grain", "s_hdr_vdo_fe";
			clocks = <0x3b 0x6 0x3b 0x7 0x3b 0x12 0x3b 0x13 0x3b 0x14>;
			compatible = "mediatek,mt8696-disp-clk";
			mediatek,pm_type = <0x4>;
			power-domains = <0x1e 0x8>;
		};

		display-pm-mm-com {
			clock-names = "hdmi_metadata", "w2d", "p2i", "sdppf", "vdoin", "vm";
			clocks = <0x3a 0x1b 0x3a 0x1d 0x3a 0x19 0x3a 0x18 0x3a 0x1c 0x3a 0x1a>;
			compatible = "mediatek,mt8696-disp-clk";
			mediatek,pm_type = <0x1>;
			power-domains = <0x1e 0x3>;
		};

		display-pm-mm-top {
			clock-names = "tvdpll", "tvdpll_d2", "osdpll", "osdpll_d2", "osdpll_d4", "hd_sel", "sd_sel", "osd_sel", "vdo3_sel", "vdo4_sel", "clk26m", "vdout_sys", "dgi", "fake_eng", "fmt_tg", "osd_fhd", "osd_fbdc", "osd_fhd_sim2miu", "fhd_gfx_fe_fifo", "fhd_hdr_gfx_fe", "hdr_adl", "disp_mix", "hdr_vdo_be", "hdr_be_fifo", "hdmi_tx_pixel", "hdmi_tx_pixel_d2";
			clocks = <0x22 0xc 0x9 0x51 0x22 0x4 0x9 0x44 0x9 0x45 0x9 0x93 0x9 0x67 0x9 0x90 0x9 0x91 0x9 0x92 0x20 0x3a 0xa 0x3a 0x17 0x3a 0x3 0x3a 0xc 0x3a 0xf 0x3a 0xe 0x3a 0x12 0x3a 0x10 0x3a 0x11 0x3a 0x13 0x3a 0xd 0x3a 0x15 0x3a 0x14 0x9 0x58 0x9 0x59>;
			compatible = "mediatek,mt8696-disp-clk";
			mediatek,pm_type = <0x0>;
			power-domains = <0x1e 0x2>;
		};

		display-pm-osd-uhd {
			clock-names = "osd_uhd", "uhd_gfx_fe_fifo", "uhd_hdr_gfx_fe";
			clocks = <0x3a 0x1e 0x3a 0x1f 0x3a 0x20>;
			compatible = "mediatek,mt8696-disp-clk";
			mediatek,pm_type = <0x2>;
			power-domains = <0x1e 0x4>;
		};

		dramc@10104000 {
			compatible = "mediatek,dramc";
			phandle = <0x6e>;
			reg = <0x0 0x10104000 0x0 0x2000 0x0 0x10114000 0x0 0x2000 0x0 0x10106000 0x0 0x1000 0x0 0x10116000 0x0 0x1000 0x0 0x10100000 0x0 0x2000 0x0 0x10110000 0x0 0x2000 0x0 0x10108000 0x0 0x1000 0x0 0x10118000 0x0 0x1000>;
		};

		earc-receiver@1a001000 {
			clock-names = "hdmi_apb_sel";
			clocks = <0x9 0xa8>;
			compatible = "mediatek,earc-rx";
			earcrx-gpios = <0x24 0x40 0x0>;
			interrupts = <0x0 0xc5 0x4>;
			phandle = <0x5a>;
			reg = <0x0 0x1a001000 0x0 0x1000 0x0 0x11f30000 0x0 0x100 0x0 0x1a000000 0x0 0x1000 0x0 0x10005000 0x0 0x2000>;
			status = "okay";
		};

		eem_fsm@1100b000 {
			compatible = "mediatek,eem_fsm";
			eem-clamp-cci = <0x0>;
			eem-clamp-little = <0x0>;
			eem-initmon-cci = <0xff>;
			eem-initmon-little = <0xff>;
			eem-offset-cci = <0xff>;
			eem-offset-little = <0xff>;
			eem-status = <0x1>;
			phandle = <0x7b>;
			reg = <0x0 0x1100b000 0x0 0x1000>;
			sn-status = <0x0>;
		};

		emi@10203000 {
			compatible = "mediatek,mt8696-emi", "mediatek,emi";
			interrupts = <0x0 0x9c 0x4>;
			phandle = <0x6f>;
			reg = <0x0 0x10203000 0x0 0x1000 0x0 0x10226000 0x0 0x1000 0x0 0x10107000 0x0 0x1000 0x0 0x10117000 0x0 0x1000>;
		};

		ethernet@1101a000 {
			clock-names = "core", "reg", "trans", "ether_axi", "ether_apb", "ether_rx", "ether_tx", "ether_rx_ext", "ether_tx_ext", "ether_mac", "ether_nclk";
			clocks = <0x14 0x17 0x14 0x19 0x9 0x9a 0x27 0x1 0x27 0x0 0x27 0x2 0x27 0x3 0x27 0x4 0x27 0x5 0x27 0x6 0x27 0x7>;
			compatible = "mediatek,mt8696-eth";
			interrupts = <0x0 0x10a 0x4>;
			phandle = <0x8a>;
			power-domains = <0x1e 0xe>;
			reg = <0x0 0x1101a000 0x0 0x380>;
			status = "disabled";
		};

		fhctl@1000ce00 {
			compatible = "mediatek,fhctl";
			reg = <0x0 0x1000ce00 0x0 0xd4>;
		};

		gce_mbox@10228000 {
			#gce-event-cells = <0x1>;
			#gce-subsys-cells = <0x2>;
			#mbox-cells = <0x3>;
			clock-names = "gce";
			clocks = <0xa 0x2>;
			compatible = "mediatek,mailbox-gce";
			default_tokens = [02 bc 02 bd 02 be 02 bf 02 c0];
			interrupts = <0x0 0xa2 0x4>;
			phandle = <0x1f>;
			reg = <0x0 0x10228000 0x0 0x4000>;
		};

		gce_mbox_svp@10228000 {
			#mbox-cells = <0x3>;
			clock-names = "gce";
			clocks = <0xa 0x2>;
			compatible = "mediatek,mailbox-gce-sec";
			interrupts = <0x0 0xa2 0x4>;
			mboxes = <0x1f 0xf 0xffffffff 0x1>;
			phandle = <0x42>;
			reg = <0x0 0x10228000 0x0 0x4000>;
		};

		gpio_keys {
			compatible = "gpio-keys";
			phandle = <0xa5>;
		};

		gpu@13000000 {
			#cooling-cells = <0x2>;
			clock-frequency = <0x26be3680>;
			compatible = "mediatek,mt8696-clovelly";
			interrupt-names = "RGX";
			interrupts = <0x0 0xfe 0x4>;
			phandle = <0x4a>;
			reg = <0x0 0x13000000 0x0 0x100000>;
		};

		hdmitx@1a000000 {
			clock-names = "hdmi_cec", "hd_sel", "sd_sel", "txpxlclk", "txpxlckd6", "hdmi_pxd3", "hdmi_hdcp", "hdmi_hdcp24", "hd20_dacrsel", "hd20_hdcpsel", "hdmi_apbsel", "hdmi_sel", "hdmi_rgb2hdmien", "hdmi_sdppf", "hdmi_p2i", "hdmi_osdpll";
			clocks = <0xa 0x7 0x9 0x93 0x9 0x67 0x9 0x58 0x9 0x5c 0x9 0xc2 0x9 0x96 0x9 0x97 0x9 0xa4 0x9 0xa5 0x9 0xa8 0x9 0xa6 0x3a 0x16 0x3a 0x18 0x3a 0x19 0x9 0xc0>;
			compatible = "mediatek,mt8696-hdmitx21";
			interrupts = <0x0 0xc4 0x4 0x0 0xc0 0x4>;
			phandle = <0xa4>;
			pinctrl-0 = <0x41>;
			pinctrl-names = "default";
			power-domains = <0x1e 0x5>;
			reg = <0x0 0x14001800 0x0 0x100 0x0 0x10014000 0x0 0x100 0x0 0x1a000000 0x0 0x1000 0x0 0x11f30000 0x0 0x100 0x0 0x14001000 0x0 0xd00>;
			status = "okay";
		};

		i2c@10018000 {
			clock-div = <0x1>;
			clock-names = "main", "dma";
			clocks = <0xa 0x6 0x14 0xa>;
			compatible = "mediatek,mt8696-i2c";
			interrupts = <0x0 0x6f 0x4>;
			phandle = <0x6d>;
			reg = <0x0 0x10018000 0x0 0x90 0x0 0x11000280 0x0 0x80>;
			status = "disabled";
		};

		i2c@11007000 {
			clock-div = <0x1>;
			clock-names = "main", "dma";
			clocks = <0x14 0x10 0x14 0xa>;
			compatible = "mediatek,mt8696-i2c";
			interrupts = <0x0 0x6a 0x4>;
			phandle = <0x77>;
			reg = <0x0 0x11007000 0x0 0x90 0x0 0x11000080 0x0 0x80>;
			status = "disabled";
		};

		i2c@11008000 {
			clock-div = <0x1>;
			clock-names = "main", "dma";
			clocks = <0x14 0x10 0x14 0xa>;
			compatible = "mediatek,mt8696-i2c";
			interrupts = <0x0 0x6b 0x4>;
			phandle = <0x78>;
			reg = <0x0 0x11008000 0x0 0x90 0x0 0x11000100 0x0 0x80>;
			status = "disabled";
		};

		i2c@11009000 {
			clock-div = <0x1>;
			clock-names = "main", "dma";
			clocks = <0x14 0x10 0x14 0xa>;
			compatible = "mediatek,mt8696-i2c";
			interrupts = <0x0 0x6c 0x4>;
			phandle = <0x79>;
			reg = <0x0 0x11009000 0x0 0x90 0x0 0x11000180 0x0 0x80>;
			status = "disabled";
		};

		i2c@11010000 {
			clock-div = <0x1>;
			clock-frequency = <0x61a80>;
			clock-names = "main", "dma";
			clocks = <0x14 0x10 0x14 0xa>;
			compatible = "mediatek,mt8696-i2c";
			interrupts = <0x0 0x6d 0x4>;
			phandle = <0x7e>;
			pinctrl-0 = <0x23>;
			pinctrl-names = "default";
			reg = <0x0 0x11010000 0x0 0x90 0x0 0x11000200 0x0 0x80>;
			status = "okay";

			mt6395@62 {
				compatible = "mediatek,mt6395-regulator";
				mt6395,irq-gpios = <0x24 0x4 0x0>;
				phandle = <0x80>;
				pinctrl-0 = <0x25>;
				pinctrl-names = "default";
				reg = <0x62>;
				status = "okay";

				mt6395_buck1 {
					phandle = <0x81>;
					regulator-always-on;
					regulator-boot-on;
					regulator-compatible = "mt6395_buck1";
					regulator-max-microvolt = <0x154456>;
					regulator-min-microvolt = <0x927c0>;
					regulator-name = "VPROC";
					regulator-ramp-delay = <0x4e20>;
				};

				mt6395_buck2 {
					phandle = <0x82>;
					regulator-always-on;
					regulator-boot-on;
					regulator-compatible = "mt6395_buck2";
					regulator-max-microvolt = <0x10c8e0>;
					regulator-min-microvolt = <0x10c8e0>;
					regulator-name = "AVDD2";
				};

				mt6395_buck3 {
					phandle = <0x83>;
					regulator-always-on;
					regulator-boot-on;
					regulator-compatible = "mt6395_buck3";
					regulator-max-microvolt = <0x1b7740>;
					regulator-min-microvolt = <0x1b7740>;
					regulator-name = "VIO18";
				};

				mt6395_buck4 {
					phandle = <0x84>;
					regulator-always-on;
					regulator-boot-on;
					regulator-compatible = "mt6395_buck4";
					regulator-max-microvolt = <0x325aa0>;
					regulator-min-microvolt = <0x325aa0>;
					regulator-name = "VIO33";
				};

				mt6395_ldo1 {
					phandle = <0x85>;
					regulator-always-on;
					regulator-boot-on;
					regulator-compatible = "mt6395_ldo1";
					regulator-max-microvolt = <0x124f80>;
					regulator-min-microvolt = <0x124f80>;
					regulator-name = "mt6395_ldo1";
				};
			};

			rt5738_buck@55 {
				compatible = "richtek,rt5738l";
				phandle = <0x7f>;
				ramp_down = <0x3>;
				ramp_up = <0x1>;
				reg = <0x55>;
				regulator-always-on;
				regulator-boot-on;
				regulator-max-microvolt = <0x13d620>;
				regulator-min-microvolt = <0x493e0>;
				regulator-name = "VSRAM";
				status = "okay";
			};
		};

		i2c@11011000 {
			clock-div = <0x1>;
			clock-names = "main", "dma";
			clocks = <0x14 0x10 0x14 0xa>;
			compatible = "mediatek,mt8696-i2c";
			interrupts = <0x0 0x6e 0x4>;
			phandle = <0x86>;
			pinctrl-0 = <0x26>;
			pinctrl-names = "default";
			reg = <0x0 0x11011000 0x0 0x90 0x0 0x11000300 0x0 0x80>;
			status = "okay";

			tmp103@70 {
				compatible = "ti,tmp103";
				device_name = "tmp103a";
				phandle = <0x87>;
				reg = <0x70>;
			};

			tmp103@72 {
				compatible = "ti,tmp103";
				device_name = "tmp103c";
				phandle = <0x88>;
				reg = <0x72>;
			};
		};

		imgresz@1500c000 {
			clock-names = "imgrz_cg";
			clocks = <0x3b 0x9>;
			compatible = "mediatek,mt8696-imgresz";
			interrupts = <0x0 0x120 0x4>;
			iommus = <0x3c 0xa9 0x3c 0xaa 0x3c 0xab>;
			mediatek,imgreszid = <0x0>;
			mediatek,larb = <0x19>;
			phandle = <0xa1>;
			power-domains = <0x1e 0x9>;
			reg = <0x0 0x1500c000 0x0 0x400 0x0 0x1500ce00 0x0 0x100>;
		};

		imgresz@1500c400 {
			clock-names = "imgrz_cg";
			clocks = <0x3b 0x9>;
			compatible = "mediatek,mt8696-imgresz";
			interrupts = <0x0 0x11f 0x4>;
			iommus = <0x3c 0xca 0x3c 0xcb 0x3c 0xcc>;
			mediatek,imgreszid = <0x1>;
			mediatek,larb = <0x1a>;
			phandle = <0xa2>;
			power-domains = <0x1e 0x9>;
			reg = <0x0 0x1500c400 0x0 0x400 0x0 0x1500cf00 0x0 0x100>;
		};

		interrupt-controller@c000000 {
			#interrupt-cells = <0x3>;
			#redistributor-regions = <0x1>;
			compatible = "arm,gic-v3";
			interrupt-controller;
			interrupt-parent = <0x1>;
			interrupts = <0x1 0x9 0x4>;
			phandle = <0x1>;
			reg = <0x0 0xc000000 0x0 0x40000 0x0 0xc040000 0x0 0x200000>;
		};

		ion {
			compatible = "mediatek,ion";
			iommus = <0x3c 0xab>;
			phandle = <0xa6>;
		};

		irrx@1000d000 {
			compatible = "mediatek,mt8696-irrx";
			interrupts = <0x0 0xb5 0x4>;
			phandle = <0x6c>;
			pinctrl-0 = <0x12>;
			pinctrl-names = "default";
			reg = <0x0 0x1000d000 0x0 0x1000>;
			status = "disabled";
		};

		irt_dma@1500b000 {
			clock-names = "irt_dma";
			clocks = <0x3b 0x8>;
			compatible = "mediatek,mt8696-irt";
			interrupts = <0x0 0x121 0x4>;
			iommus = <0x3c 0xcd>;
			mediatek,larb = <0x1a>;
			phandle = <0xa0>;
			power-domains = <0x1e 0x9>;
			reg = <0x0 0x1500b000 0x0 0x100 0x0 0x15000000 0x0 0x100>;
		};

		larb@14000000 {
			clock-names = "apb", "smi";
			clocks = <0x3a 0x2 0x3b 0x5>;
			compatible = "mediatek,mt8696-smi-larb";
			mediatek,larb-id = <0x8>;
			mediatek,smi = <0x39>;
			phandle = <0x1c>;
			power-domains = <0x1e 0x7>;
			reg = <0x0 0x14000000 0x0 0x1000>;
		};

		larb@1400c000 {
			clock-names = "apb", "smi";
			clocks = <0x3a 0x1 0x3a 0x21>;
			compatible = "mediatek,mt8696-smi-larb";
			mediatek,larb-id = <0x0>;
			mediatek,smi = <0x39>;
			phandle = <0x15>;
			power-domains = <0x1e 0x4>;
			reg = <0x0 0x1400c000 0x0 0x1000>;
		};

		larb@1400e000 {
			clock-names = "apb", "smi";
			clocks = <0x3a 0x4 0x3a 0x4>;
			compatible = "mediatek,mt8696-smi-larb";
			mediatek,larb-id = <0x4>;
			mediatek,smi = <0x39>;
			phandle = <0x18>;
			power-domains = <0x1e 0x2>;
			reg = <0x0 0x1400e000 0x0 0x1000>;
		};

		larb@15004000 {
			clock-names = "apb", "smi";
			clocks = <0x3a 0x6 0x3b 0x3>;
			compatible = "mediatek,mt8696-smi-larb";
			mediatek,larb-id = <0x5>;
			mediatek,smi = <0x39>;
			phandle = <0x19>;
			power-domains = <0x1e 0x7>;
			reg = <0x0 0x15004000 0x0 0x1000>;
		};

		larb@15005000 {
			clock-names = "apb", "smi";
			clocks = <0x3a 0x7 0x3b 0x4>;
			compatible = "mediatek,mt8696-smi-larb";
			mediatek,larb-id = <0x6>;
			mediatek,smi = <0x39>;
			phandle = <0x1a>;
			power-domains = <0x1e 0x7>;
			reg = <0x0 0x15005000 0x0 0x1000>;
		};

		larb@1600d000 {
			clock-names = "apb", "smi";
			clocks = <0x3a 0x8 0x3f 0x0>;
			compatible = "mediatek,mt8696-smi-larb";
			mediatek,larb-id = <0x7>;
			mediatek,smi = <0x39>;
			phandle = <0x1b>;
			power-domains = <0x1e 0x14>;
			reg = <0x0 0x1600d000 0x0 0x1000>;
		};

		larb@1602e000 {
			clock-names = "apb", "smi";
			clocks = <0x3a 0x5 0x3e 0x0>;
			compatible = "mediatek,mt8696-smi-larb";
			mediatek,larb-id = <0x1>;
			mediatek,smi = <0x39>;
			phandle = <0x16>;
			power-domains = <0x1e 0x0>;
			reg = <0x0 0x1602e000 0x0 0x1000>;
		};

		larb@18002000 {
			clock-names = "apb", "smi";
			clocks = <0x3a 0xb 0x40 0x0>;
			compatible = "mediatek,mt8696-smi-larb";
			mediatek,larb-id = <0x3>;
			mediatek,smi = <0x39>;
			phandle = <0x17>;
			power-domains = <0x1e 0x1>;
			reg = <0x0 0x18002000 0x0 0x1000>;
		};

		m4u@10205000 {
			#iommu-cells = <0x1>;
			clock-names = "bclk", "apb";
			clocks = <0xa 0x3 0x14 0x1b>;
			compatible = "mediatek,mt8696-m4u";
			interrupts = <0x0 0xa3 0x4>;
			mediatek,larbs = <0x15 0x16 0x17 0x18 0x19 0x1a 0x1b 0x1c>;
			phandle = <0x3c>;
			reg = <0x0 0x10205000 0x0 0x1000>;
		};

		m4u@1020e000 {
			#iommu-cells = <0x1>;
			compatible = "mediatek,sec_m4u";
			interrupts = <0x0 0xa4 0x4>;
			phandle = <0x71>;
			reg = <0x0 0x1020e000 0x0 0x1000>;
		};

		mcupm@c540000 {
			compatible = "mediatek,mcupm";
			interrupt-names = "mbox0", "mbox1", "mbox2", "mbox3", "mbox4", "mbox5", "mbox6", "mbox7";
			interrupts = <0x0 0x21 0x4 0x0 0x22 0x4 0x0 0x23 0x4 0x0 0x24 0x4 0x0 0x25 0x4 0x0 0x26 0x4 0x0 0x27 0x4 0x0 0x28 0x4>;
			phandle = <0x69>;
			reg = <0x0 0xc540000 0x0 0x22000 0x0 0xc55fb00 0x0 0xa0 0x0 0xc562004 0x0 0x4 0x0 0xc562018 0x0 0x4 0x0 0xc562000 0x0 0x4 0x0 0xc562010 0x0 0x4 0x0 0xc55fba0 0x0 0xa0 0x0 0xc562004 0x0 0x4 0x0 0xc562018 0x0 0x4 0x0 0xc562000 0x0 0x4 0x0 0xc562010 0x0 0x4 0x0 0xc55fc40 0x0 0xa0 0x0 0xc562004 0x0 0x4 0x0 0xc562018 0x0 0x4 0x0 0xc562000 0x0 0x4 0x0 0xc562010 0x0 0x4 0x0 0xc55fce0 0x0 0xa0 0x0 0xc562004 0x0 0x4 0x0 0xc562018 0x0 0x4 0x0 0xc562000 0x0 0x4 0x0 0xc562010 0x0 0x4 0x0 0xc55fd80 0x0 0xa0 0x0 0xc562004 0x0 0x4 0x0 0xc562018 0x0 0x4 0x0 0xc562000 0x0 0x4 0x0 0xc562010 0x0 0x4 0x0 0xc55fe20 0x0 0xa0 0x0 0xc562004 0x0 0x4 0x0 0xc562018 0x0 0x4 0x0 0xc562000 0x0 0x4 0x0 0xc562010 0x0 0x4 0x0 0xc55fec0 0x0 0xa0 0x0 0xc562004 0x0 0x4 0x0 0xc562018 0x0 0x4 0x0 0xc562000 0x0 0x4 0x0 0xc562010 0x0 0x4 0x0 0xc55ff60 0x0 0xa0 0x0 0xc562004 0x0 0x4 0x0 0xc562018 0x0 0x4 0x0 0xc562000 0x0 0x4 0x0 0xc562010 0x0 0x4>;
			reg-names = "mcupm_base", "mbox0_base", "mbox0_set", "mbox0_clr", "mbox0_send", "mbox0_recv", "mbox1_base", "mbox1_set", "mbox1_clr", "mbox1_send", "mbox1_recv", "mbox2_base", "mbox2_set", "mbox2_clr", "mbox2_send", "mbox2_recv", "mbox3_base", "mbox3_set", "mbox3_clr", "mbox3_send", "mbox3_recv", "mbox4_base", "mbox4_set", "mbox4_clr", "mbox4_send", "mbox4_recv", "mbox5_base", "mbox5_set", "mbox5_clr", "mbox5_send", "mbox5_recv", "mbox6_base", "mbox6_set", "mbox6_clr", "mbox6_send", "mbox6_recv", "mbox7_base", "mbox7_set", "mbox7_clr", "mbox7_send", "mbox7_recv";
		};

		mfg@13fbf000 {
			clock-names = "mfg_sel", "pll", "univpll624m", "univpll416m", "univpll312m";
			clocks = <0x9 0x6c 0x22 0xd 0x9 0x13 0x9 0x18 0x9 0x14>;
			compatible = "mediatek,mt8696-mfg";
			phandle = <0x91>;
			reg = <0x0 0x13fbf000 0x0 0x1000>;
			reg-vgpu-supply = <0xb>;
		};

		mfg_2d {
			compatible = "mediatek,mt8696-mfg-2d";
			phandle = <0xa8>;
			power-domains = <0x1e 0x11>;
		};

		mfg_3d {
			compatible = "mediatek,mt8696-mfg-3d";
			phandle = <0xa9>;
			power-domains = <0x1e 0x12>;
		};

		mfg_async {
			compatible = "mediatek,mt8696-mfg-async";
			phandle = <0xa7>;
			power-domains = <0x1e 0x10>;
		};

		mmc@11230000 {
			bus-width = <0x8>;
			cap-cqe;
			cap-cqe_dcmd;
			cap-mmc-highspeed;
			clock-names = "source", "hclk", "source_cg", "hclk_cg";
			clocks = <0x9 0x73 0x14 0x1f 0x14 0x1c 0x14 0xb>;
			compatible = "mediatek,mt8696-mmc";
			hs400-ds-delay = <0x13014>;
			interrupts = <0x0 0x65 0x4>;
			max-frequency = <0xbebc200>;
			mmc-hs200-1_8v;
			mmc-hs400-1_8v;
			no-sd;
			no-sdio;
			non-removable;
			phandle = <0x8d>;
			pinctrl-0 = <0x2e>;
			pinctrl-1 = <0x2f>;
			pinctrl-names = "default", "state_uhs";
			reg = <0x0 0x11230000 0x0 0x1000 0x0 0x11e00000 0x0 0x1000>;
			status = "okay";
			vmmc-supply = <0x30>;
			vqmmc-supply = <0x31>;
		};

		mmc@11240000 {
			clock-names = "source", "hclk", "source_cg";
			clocks = <0x9 0x74 0x14 0xc 0x14 0x1d>;
			compatible = "mediatek,mt8696-mmc";
			interrupts = <0x0 0x66 0x4>;
			phandle = <0x8e>;
			reg = <0x0 0x11240000 0x0 0x1000 0x0 0x11d10000 0x0 0x1000>;
			status = "disabled";
		};

		mtkfb {
			compatible = "mediatek,mtkfb";
			iommus = <0x3c 0x0 0x3c 0x1 0x3c 0x2 0x3c 0x3 0x3c 0x80 0x3c 0x81 0x3c 0x82 0x3c 0x83 0x3c 0x84 0x3c 0x85 0x3c 0x86 0x3c 0x87 0x3c 0x88 0x3c 0x89 0x3c 0x8a 0x3c 0xa0 0x3c 0xa1 0x3c 0xa2 0x3c 0xa3 0x3c 0xa4 0x3c 0xa5 0x3c 0xa6 0x3c 0xa7 0x3c 0xa8 0x3c 0xa9 0x3c 0xaa 0x3c 0xab 0x3c 0xac 0x3c 0xad 0x3c 0xae 0x3c 0xc0 0x3c 0xc1 0x3c 0xc2 0x3c 0xc3 0x3c 0xc4 0x3c 0xc5 0x3c 0xc6 0x3c 0xc7 0x3c 0xc8 0x3c 0xc9 0x3c 0xca 0x3c 0xcb 0x3c 0xcc 0x3c 0xcd 0x3c 0xce 0x3c 0xcf 0x3c 0xd0>;
			mboxes = <0x1f 0x4 0xffffffff 0x1 0x1f 0x5 0xffffffff 0x4 0x1f 0x0 0xffffffff 0x4 0x42 0x8 0xffffffff 0x4>;
			mediatek,larb = <0x15 0x18 0x19 0x1a>;
			phandle = <0xaa>;
		};

		nfi@1100e000 {
			clock-names = "nfi_clk", "nfi2x_sel", "nfi2x_clk_parent";
			clocks = <0x14 0x0 0x9 0xa2 0x9 0x15>;
			compatible = "mediatek,mt8696-nfc";
			interrupts = <0x0 0x76 0x4 0x0 0x75 0x4>;
			phandle = <0x7d>;
			reg = <0x0 0x1100e000 0x0 0x1000 0x0 0x1100f000 0x0 0x1000>;
			status = "disabled";
		};

		nna_top_ports_wrapper@10216000 {
			clock-names = "nna0_sel", "nna0", "nna0_pwr", "nna0_26men";
			clocks = <0x9 0xa7 0x1d 0x0 0x1d 0x2 0x1d 0x1>;
			compatible = "amazon,nna-1.0";
			interrupt-names = "nna_interrupt";
			interrupt-parent = <0x1>;
			interrupts = <0x0 0x107 0x4>;
			phandle = <0x73>;
			power-domains = <0x1e 0xf>;
			reg = <0x0 0x10216000 0x0 0x1000>;
		};

		pinctrl@1000b000 {
			#gpio-cells = <0x2>;
			#interrupt-cells = <0x4>;
			compatible = "mediatek,mt8696-pinctrl";
			gpio-controller;
			interrupt-controller;
			interrupts = <0x0 0xa9 0x4>;
			mediatek,pctl-regmap = <0xc 0xd 0xe 0xf 0x10 0x11>;
			phandle = <0x24>;
			pins-are-numbered;
			reg = <0x0 0x1000b000 0x0 0x1000>;

			dat1_eint {
				phandle = <0x34>;

				pins_dat1 {
					bias-pull-up = <0x65>;
					input-enable;
					pinmux = <0x2c00>;
				};
			};

			hdmi {
				phandle = <0x41>;

				hdmi_5vctl {
					pinmux = <0x200>;
				};

				hdmi_cec {
					bias-disable;
					pinmux = <0x6e01>;
				};

				hdmi_hotplug {
					bias-pull-down;
					pinmux = <0x6f01>;
				};

				hdmi_pins {
					bias-disable;
					pinmux = <0x7001 0x7101>;
				};
			};

			i2c3 {
				phandle = <0x23>;

				pins_bus {
					bias-pull-up = <0x6a>;
					drive-strength = <0x65>;
					input-enable;
					pinmux = <0x4a01 0x4901>;
				};
			};

			i2c5 {
				phandle = <0x26>;

				pins_bus {
					bias-disable;
					drive-strength = <0x65>;
					input-enable;
					pinmux = <0x7301 0x7201>;
				};
			};

			irrx_pin_ir {
				phandle = <0x12>;

				pins_cmd_dat {
					bias-disable;
					pinmux = <0x3f03>;
				};
			};

			mmc0 {
				phandle = <0x2f>;

				pins_clk {
					bias-pull-down = <0x66>;
					drive-strength = <0x4>;
					pinmux = <0x3001>;
				};

				pins_cmd_dat {
					bias-pull-up = <0x65>;
					drive-strength = <0x8>;
					input-enable;
					pinmux = <0x3801 0x3701 0x3601 0x3501 0x3401 0x3301 0x3201 0x3101 0x3901>;
				};

				pins_ds {
					bias-pull-down = <0x66>;
					drive-strength = <0x6>;
					pinmux = <0x2f01>;
				};

				pins_rst {
					bias-pull-up;
					pinmux = <0x3a01>;
				};
			};

			mmc0default {
				phandle = <0x2e>;

				pins_clk {
					bias-pull-down;
					pinmux = <0x3001>;
				};

				pins_cmd_dat {
					bias-pull-up;
					input-enable;
					pinmux = <0x3801 0x3701 0x3601 0x3501 0x3401 0x3301 0x3201 0x3101 0x3901>;
				};

				pins_rst {
					bias-pull-up;
					pinmux = <0x3a01>;
				};
			};

			mmc2 {
				phandle = <0x33>;

				pins_clk {
					bias-pull-down = <0x66>;
					drive-strength = <0x6>;
					pinmux = <0x2801>;
				};

				pins_cmd_dat {
					bias-pull-up = <0x65>;
					drive-strength = <0x4>;
					input-enable;
					pinmux = <0x2d01 0x2c01 0x2b01 0x2a01 0x2e01>;
				};

				pins_ds {
					bias-pull-down = <0x66>;
					drive-strength = <0x4>;
					pinmux = <0x2901>;
				};
			};

			mmc2default {
				phandle = <0x32>;

				pins_clk {
					bias-pull-down = <0x66>;
					drive-strength = <0x6>;
					pinmux = <0x2801>;
				};

				pins_cmd_dat {
					bias-pull-up = <0x65>;
					drive-strength = <0x4>;
					input-enable;
					pinmux = <0x2d01 0x2c01 0x2b01 0x2a01 0x2e01>;
				};
			};

			pmic_pins_eint {
				phandle = <0x25>;

				pmic_pins {
					bias-disable;
					pinmux = <0x400>;
				};
			};

			sdio_dat1 {
				phandle = <0x35>;

				pins_dat1 {
					bias-pull-up = <0x65>;
					drive-strength = <0x4>;
					input-enable;
					pinmux = <0x2c01>;
				};
			};

			sdio_low {
				phandle = <0x36>;

				pins_low {
					bias-disable;
					input-disable;
					pinmux = <0x2d00 0x2b00 0x2a00 0x2e00 0x2900>;
				};
			};
		};

		pseudo-m4u {
			compatible = "mediatek,mtk-pseudo-m4u";
			iommus = <0x3c 0xab>;
		};

		rng@1020f000 {
			clock-names = "rng";
			clocks = <0xa 0xf>;
			compatible = "mediatek,mt8696-rng", "mediatek,mt7623-rng";
			phandle = <0x72>;
			reg = <0x0 0x1020f000 0x0 0x100>;
		};

		sdio@11250000 {
			bus-width = <0x4>;
			cap-sd-highspeed;
			cap-sdio-irq;
			clock-names = "source", "hclk", "source_cg", "hclk_cg";
			clocks = <0x9 0x75 0x14 0x20 0x14 0x1e 0x14 0xd>;
			compatible = "mediatek,mt8696-sdio";
			eint-gpios = <0x24 0x2c 0x0>;
			enable-sdio-wakeup;
			interrupts = <0x0 0x67 0x4>;
			keep-power-in-suspend;
			max-frequency = <0xbebc200>;
			no-mmc;
			no-sd;
			non-removable;
			phandle = <0x8f>;
			pinctrl-0 = <0x32>;
			pinctrl-1 = <0x33>;
			pinctrl-2 = <0x34>;
			pinctrl-3 = <0x35>;
			pinctrl-4 = <0x36>;
			pinctrl-names = "default", "state_uhs", "state_eint", "state_dat1", "state_low";
			reg = <0x0 0x11250000 0x0 0x1000 0x0 0x11c00000 0x0 0x1000>;
			sd-uhs-sdr104;
			sd-uhs-sdr25;
			sd-uhs-sdr50;
			status = "okay";
			vmmc-supply = <0x37>;
			vqmmc-supply = <0x38>;
		};

		serial@10049000 {
			clock-names = "baud", "bus";
			clocks = <0x20 0xa 0xb>;
			compatible = "mediatek,mt8696-uart", "mediatek,mt6577-uart";
			interrupts = <0x0 0x73 0x4>;
			phandle = <0x76>;
			reg = <0x0 0x11002800 0x0 0x1000>;
			status = "disabled";
		};

		serial@11002000 {
			clock-names = "baud", "bus";
			clocks = <0x20 0x14 0xe>;
			compatible = "mediatek,mt8696-uart", "mediatek,mt6577-uart";
			interrupts = <0x0 0x71 0x4>;
			phandle = <0x74>;
			reg = <0x0 0x11002000 0x0 0x1000>;
			status = "okay";
		};

		serial@11002400 {
			clock-names = "baud", "bus";
			clocks = <0x20 0x14 0xf>;
			compatible = "mediatek,mt8696-uart", "mediatek,mt6577-uart";
			interrupts = <0x0 0x72 0x4>;
			phandle = <0x75>;
			reg = <0x0 0x11002400 0x0 0x1000>;
			status = "okay";
		};

		smi@1400d000 {
			clock-names = "apb", "smi";
			clocks = <0x3a 0x0 0x3a 0x0>;
			compatible = "mediatek,mt8696-smi-common";
			phandle = <0x39>;
			power-domains = <0x1e 0x2>;
			reg = <0x0 0x1400d000 0x0 0x1000>;
		};

		soc_data@8000000 {
			#address-cells = <0x1>;
			#size-cells = <0x1>;
			compatible = "mediatek,mt8696-efuse", "mediatek,efuse";
			phandle = <0x67>;
			reg = <0x0 0x8000000 0x0 0x10>;
		};

		spi@1100a000 {
			#address-cells = <0x1>;
			#size-cells = <0x0>;
			clock-names = "parent-clk", "sel-clk", "spi-clk";
			clocks = <0x9 0x19 0x9 0x6f 0x14 0x13>;
			compatible = "mediatek,ipm-spi";
			interrupts = <0x0 0x8b 0x4>;
			phandle = <0x7a>;
			reg = <0x0 0x1100a000 0x0 0x1000>;
			status = "disabled";
		};

		spi@11015000 {
			#address-cells = <0x1>;
			#size-cells = <0x0>;
			clock-names = "parent-clk", "sel-clk", "spi-clk";
			clocks = <0x9 0x19 0x9 0x6f 0x14 0x15>;
			compatible = "mediatek,ipm-spi";
			interrupts = <0x0 0x8c 0x4>;
			phandle = <0x89>;
			reg = <0x0 0x11015000 0x0 0x1000>;
			status = "disabled";
		};

		stc@10008000 {
			compatible = "mediatek,gpt-stc";
			phandle = <0x6b>;
			reg = <0x0 0x10008000 0x0 0x40>;
		};

		sys_timer@10017000 {
			clocks = <0x13>;
			compatible = "mediatek,sys_timer";
			interrupts = <0x0 0xc1 0x4>;
			reg = <0x0 0x10017000 0x0 0x1000>;
			reg-names = "sys_timer_base";
		};

		syscfg_pctl_0@11c30000 {
			compatible = "mediatek,pctl-0-syscfg", "syscon";
			phandle = <0xd>;
			reg = <0x0 0x11c30000 0x0 0x1000>;
		};

		syscfg_pctl_1@11d00000 {
			compatible = "mediatek,pctl-1-syscfg", "syscon";
			phandle = <0xe>;
			reg = <0x0 0x11d00000 0x0 0x1000>;
		};

		syscfg_pctl_2@11d20000 {
			compatible = "mediatek,pctl-2-syscfg", "syscon";
			phandle = <0xf>;
			reg = <0x0 0x11d20000 0x0 0x1000>;
		};

		syscfg_pctl_3@11e10000 {
			compatible = "mediatek,pctl-3-syscfg", "syscon";
			phandle = <0x10>;
			reg = <0x0 0x11e10000 0x0 0x1000>;
		};

		syscfg_pctl_4@11f40000 {
			compatible = "mediatek,pctl-4-syscfg", "syscon";
			phandle = <0x11>;
			reg = <0x0 0x11f40000 0x0 0x1000>;
		};

		syscfg_pctl_a@10005000 {
			compatible = "mediatek,pctl-a-syscfg", "syscon";
			phandle = <0xc>;
			reg = <0x0 0x10005000 0x0 0x1000>;
		};

		syscon@10000000 {
			#clock-cells = <0x1>;
			compatible = "mediatek,mt8696-topckgen", "syscon";
			phandle = <0x9>;
			reg = <0x0 0x10000000 0x0 0x1000>;
		};

		syscon@10001000 {
			#clock-cells = <0x1>;
			compatible = "mediatek,mt8696-infracfg", "syscon";
			phandle = <0xa>;
			reg = <0x0 0x10001000 0x0 0x1000>;
		};

		syscon@10003000 {
			#clock-cells = <0x1>;
			compatible = "mediatek,mt8696-pericfg", "syscon";
			phandle = <0x14>;
			reg = <0x0 0x10003000 0x0 0x1000>;
		};

		syscon@10006000 {
			#power-domain-cells = <0x1>;
			clock-names = "mm", "vdec-0", "venc-0", "mm-0", "mm-1", "osd-0", "hdmiapb", "mmcu-0", "mmcu-1", "mmcu-2", "audio", "ether";
			clocks = <0x9 0x68 0x9 0x69 0x9 0x6b 0x9 0x69 0x9 0x6b 0x9 0x68 0x9 0xa8 0x9 0x8e 0x9 0x64 0xa 0xd 0x9 0x7a 0x9 0x9b>;
			compatible = "mediatek,mt8696-scpsys", "syscon";
			infracfg = <0xa>;
			mfg-supply = <0xb>;
			phandle = <0x1e>;
			reg = <0x0 0x10006000 0x0 0x1000>;
		};

		syscon@1000c000 {
			#clock-cells = <0x1>;
			compatible = "mediatek,mt8696-apmixedsys", "syscon";
			phandle = <0x22>;
			reg = <0x0 0x1000c000 0x0 0x1000>;
		};

		syscon@10218000 {
			#clock-cells = <0x1>;
			compatible = "mediatek,mt8696-nna", "syscon";
			phandle = <0x1d>;
			reg = <0x0 0x10218000 0x0 0x1000>;
		};

		syscon@1101a000 {
			#clock-cells = <0x1>;
			compatible = "mediatek,mt8696-ether", "syscon";
			phandle = <0x27>;
			reg = <0x0 0x1101a000 0x0 0x1000>;
		};

		syscon@13fbf000 {
			#clock-cells = <0x1>;
			compatible = "mediatek,mt8696-mfgcfg", "syscon";
			phandle = <0x92>;
			reg = <0x0 0x13fbf000 0x0 0x1000>;
		};

		syscon@14000000 {
			#clock-cells = <0x1>;
			compatible = "mediatek,mt8696-mmsys", "syscon";
			phandle = <0x3a>;
			reg = <0x0 0x14000000 0x0 0x1000>;
		};

		syscon@15000000 {
			#clock-cells = <0x1>;
			compatible = "mediatek,mt8696-disp", "syscon";
			phandle = <0x3b>;
			reg = <0x0 0x15000000 0x0 0x1000>;
		};

		syscon@18000000 {
			#clock-cells = <0x1>;
			compatible = "mediatek,mt8696-vencsys", "syscon";
			phandle = <0x40>;
			reg = <0x0 0x18000000 0x0 0x1000>;
		};

		syscon@c53a000 {
			#clock-cells = <0x1>;
			compatible = "mediatek,mt8696-mcucfg", "syscon";
			phandle = <0x68>;
			reg = <0x0 0xc53a000 0x0 0x1000>;
		};

		systracker@10208000 {
			compatible = "mediatek,bus_dbg-v2";
			interrupts = <0x0 0x99 0x8>;
			mediatek,bus_dbg_con_offset = <0x2fc>;
			phandle = <0x70>;
			reg = <0x0 0x10208000 0x0 0x1000 0x0 0x10001000 0x0 0x1000>;
		};

		thermal-sensor {
			#thermal-sensor-cells = <0x0>;
			compatible = "generic-adc-thermal";
			io-channel-names = "sensor-channel";
			io-channels = <0x21 0x0 0x21 0x1 0x21 0x2>;
			phandle = <0x7c>;
		};

		thermal@1100b800 {
			#thermal-sensor-cells = <0x0>;
			auxadc = <0x21>;
			clock-names = "therm", "auxadc";
			clocks = <0x14 0x1 0x14 0x12>;
			compatible = "mediatek,mt8696-thermal";
			interrupts = <0x0 0x64 0x4>;
			mediatek,apmixed = <0x22>;
			mediatek,infracfg_ao = <0xa>;
			phandle = <0x4b>;
			reg = <0x0 0x1100b800 0x0 0x200>;
			status = "okay";
		};

		toprgu@10007000 {
			#reset-cells = <0x1>;
			compatible = "mediatek,mt8696-rgu";
			interrupts = <0x0 0x60 0x2>;
			phandle = <0x6a>;
			reg = <0x0 0x10007000 0x0 0x1000>;
			registered-in-atf = <0x1>;
		};

		usb-phy@11c20000 {
			#address-cells = <0x2>;
			#size-cells = <0x2>;
			compatible = "mediatek,mt8696", "mediatek,generic-tphy-v2";
			phandle = <0x90>;
			ranges;
			status = "okay";

			usb-phy@11c20000 {
				#phy-cells = <0x1>;
				clock-names = "ref";
				clocks = <0x9 0xc7>;
				mediatek,discth = <0x8>;
				phandle = <0x28>;
				reg = <0x0 0x11c20000 0x0 0x700>;
				status = "okay";
			};

			usb-phy@11c20700 {
				#phy-cells = <0x1>;
				clock-names = "ref";
				clocks = <0x9 0xc6>;
				phandle = <0x2b>;
				reg = <0x0 0x11c20700 0x0 0x900>;
				status = "disabled";
			};

			usb-phy@11c21000 {
				#phy-cells = <0x1>;
				clock-names = "ref";
				clocks = <0x9 0xc7>;
				mediatek,discth = <0x8>;
				phandle = <0x29>;
				reg = <0x0 0x11c21000 0x0 0x700>;
				status = "disabled";
			};

			usb-phy@11c22000 {
				#phy-cells = <0x1>;
				clock-names = "ref";
				clocks = <0x9 0xc7>;
				mediatek,discth = <0x8>;
				phandle = <0x2a>;
				reg = <0x0 0x11c22000 0x0 0x700>;
				status = "disabled";
			};
		};

		usb@11201000 {
			#address-cells = <0x2>;
			#size-cells = <0x2>;
			clock-names = "sys_ck", "free_ck", "ahb_ck";
			clocks = <0x14 0x9 0x9 0xc5 0x9 0x71>;
			compatible = "mediatek,mt8696-mtu3", "mediatek,mtu3";
			default_mode = "peripheral";
			dr_mode = "otg";
			enable-manual-drd;
			interrupts = <0x0 0x90 0x4>;
			maximum-speed = "high-speed";
			phandle = <0x8b>;
			phys = <0x28 0x3 0x29 0x3 0x2a 0x3 0x2b 0x4>;
			power-domains = <0x1e 0xd>;
			ranges;
			reg = <0x0 0x11201000 0x0 0x2e00 0x0 0x11203e00 0x0 0x100>;
			reg-names = "mac", "ippc";
			status = "okay";
			u3-should-port = <0x0>;
			vbus-supply = <0x2d>;
			vusb33-supply = <0x2c>;

			xhci@11200000 {
				clock-names = "sys_ck", "free_ck", "ahb_ck";
				clocks = <0x14 0x9 0x9 0xc5 0x9 0x71>;
				compatible = "mediatek,mt8696-xhci", "mediatek,mtk-xhci";
				interrupts = <0x0 0x91 0x4>;
				mediatek,syscon-wakeup = <0x14>;
				mediatek,wakeup-src = <0x3>;
				phandle = <0x8c>;
				reg = <0x0 0x11200000 0x0 0x1000>;
				reg-names = "mac";
				status = "okay";
			};
		};

		vcu@16000000 {
			compatible = "mediatek-vcu";
			gce-event-names = "venc_eof", "venc_cmdq_pause_done", "venc_mb_done", "venc_sps_done", "venc_pps_done", "venc_128B_cnt_done";
			gce-events = <0x1f 0x181 0x1f 0x182 0x1f 0x183 0x1f 0x188 0x1f 0x187 0x1f 0x184>;
			iommus = <0x3c 0x20>;
			mboxes = <0x1f 0x6 0x0 0x1>;
			mediatek,enc_gce_th_num = <0x1>;
			mediatek,mailbox-gce = <0x1f>;
			mediatek,vcuid = <0x0>;
			mediatek,vcuname = "vcu";
			phandle = <0x3d>;
			reg = <0x0 0x16000000 0x0 0x40000 0x0 0x18010000 0x0 0x10000>;
		};

		vdec@16000000 {
			clock-names = "MT_VDECEN", "MT_VDEC_L1EN", "MT_VDSOC_VSEN", "MT_VDSOC_L1_SOCEN", "MT_VDSOC_LSEN", "MT_TOPCK_SLOW_SELEN";
			clocks = <0x3e 0x3 0x3e 0x0 0x3f 0x3 0x3f 0x0 0x3f 0x1 0x9 0x6a>;
			compatible = "mediatek,mt8696-vcodec-dec";
			interrupts = <0x0 0xf3 0x4 0x0 0xf2 0x4 0x0 0x13d 0x4>;
			iommus = <0x3c 0x20 0x3c 0x21 0x3c 0x22 0x3c 0x23 0x3c 0x24 0x3c 0x25 0x3c 0x26 0x3c 0x27 0x3c 0x28 0x3c 0x29 0x3c 0xe0 0x3c 0xe1 0x3c 0xe2 0x3c 0xe3 0x3c 0xe4 0x3c 0xe5 0x3c 0xe6>;
			mediatek,larb = <0x16 0x1b>;
			mediatek,vcu = <0x3d>;
			power-domains = <0x1e 0x14>;
			reg = <0x0 0x16000000 0x0 0x1000 0x0 0x16020000 0x0 0x1000 0x0 0x16025000 0x0 0x4000 0x0 0x16010000 0x0 0x7000 0x0 0x16004000 0x0 0x1000>;
		};

		vdec@16020000 {
			compatible = "mediatek,vdec";
			interrupts = <0x0 0xf3 0x4>;
			phandle = <0xa3>;
			reg = <0x0 0x16020000 0x0 0xd000>;
		};

		vdec_core@16000000 {
			compatible = "mediatek,mt8696-vcodec-dec-core0";
			power-domains = <0x1e 0x0>;
		};

		vdec_gcon@1602f000 {
			#clock-cells = <0x1>;
			compatible = "mediatek,vdec_gcon", "syscon";
			phandle = <0x3e>;
			reg = <0x0 0x1602f000 0x0 0x10000>;
		};

		vdec_soc_gcon@1600f000 {
			#clock-cells = <0x1>;
			compatible = "mediatek,vdec_soc_gcon", "syscon";
			phandle = <0x3f>;
			reg = <0x0 0x1600f000 0x0 0x10000>;
		};

		venc@18010000 {
			clock-names = "MT_VENC_SMI", "MT_VENC_CON";
			clocks = <0x40 0x0 0x40 0x1>;
			compatible = "mediatek,mt8696-vcodec-enc";
			interrupts = <0x0 0xf0 0x4>;
			iommus = <0x3c 0x60 0x3c 0x61 0x3c 0x62 0x3c 0x63 0x3c 0x64 0x3c 0x65 0x3c 0x66 0x3c 0x67 0x3c 0x68>;
			mediatek,larb = <0x17>;
			mediatek,vcu = <0x3d>;
			power-domains = <0x1e 0x1>;
			reg = <0x0 0x18010000 0x0 0x2000>;
		};

		vq@14000000 {
			clock-names = "nr", "nr_sel", "univpll_d2", "vdo_di", "dispfmt_di", "wr_channel", "dramc_larb8", "di_sel", "tvdpll_d2", "osdpll_d3";
			clocks = <0x3b 0xc 0x9 0x94 0x9 0x18 0x3b 0xa 0x3b 0xb 0x3b 0xd 0x3b 0x5 0x9 0xa1 0x9 0x51 0x9 0x47>;
			compatible = "mediatek,mt8696-vq";
			interrupts = <0x0 0x122 0x4 0x0 0x123 0x4 0x0 0x124 0x4 0x0 0x125 0x4 0x0 0x126 0x4 0x0 0x127 0x4>;
			iommus = <0x3c 0x100 0x3c 0x101>;
			mediatek,larb = <0x1c>;
			phandle = <0x93>;
			power-domains = <0x1e 0x9>;
			reg = <0x0 0x14000000 0x0 0x1000 0x0 0x14001500 0x0 0x100 0x0 0x15000000 0x0 0x100 0x0 0x1500a000 0x0 0x1000 0x0 0x1500e000 0x0 0x1000 0x0 0x1500f000 0x0 0x100>;
		};
	};

	sound {
		compatible = "mediatek,mt8696-evb";
		mediatek,platform = <0x58>;
		phandle = <0xb6>;
		status = "okay";
	};

	sound1 {
		compatible = "mediatek,mt8696-card1";
		mediatek,multi-in-audio-codec = <0x5a>;
		mediatek,multi-in-codec-dai-name = "mtk-earc-rx-codec-dai";
		mediatek,platform = <0x59>;
		phandle = <0xb7>;
		status = "okay";
	};

	thermal-zones {

		bottom_thermal {
			policy = "trip_step_wise";
			polling-delay = <0x3e8>;
			polling-delay-passive = <0x64>;
			sustainable-power = <0x866>;
			thermal-sensors = <0x50>;

			cooling-maps {

				cpucore_cooling_map0 {
					contribution = <0x400>;
					cooling-device = <0x48 0x0 0x0>;
					trip = <0x51>;
				};

				cpucore_cooling_map1 {
					contribution = <0x400>;
					cooling-device = <0x48 0x0 0x0>;
					trip = <0x52>;
				};

				cpucore_cooling_map2 {
					cooling-device = <0x48 0x0 0x1>;
					trip = <0x53>;
				};

				cpufreq_cooling_map0 {
					contribution = <0x400>;
					cooling-device = <0x45 0x0 0x4>;
					trip = <0x51>;
				};

				cpufreq_cooling_map1 {
					contribution = <0x400>;
					cooling-device = <0x45 0x4 0x6>;
					trip = <0x52>;
				};

				cpufreq_cooling_map2 {
					contribution = <0x400>;
					cooling-device = <0x45 0x6 0x8>;
					trip = <0x53>;
				};

				gpufreq_cooling_map0 {
					contribution = <0x400>;
					cooling-device = <0x4a 0x0 0x0>;
					trip = <0x51>;
				};

				gpufreq_cooling_map1 {
					contribution = <0x400>;
					cooling-device = <0x4a 0x0 0x1>;
					trip = <0x52>;
				};

				gpufreq_cooling_map2 {
					contribution = <0x400>;
					cooling-device = <0x4a 0x1 0x3>;
					trip = <0x53>;
				};

				wifi_cooling_map0 {
					contribution = <0x400>;
					cooling-device = <0x49 0x0 0x0>;
					trip = <0x51>;
				};

				wifi_cooling_map1 {
					contribution = <0x400>;
					cooling-device = <0x49 0x0 0x0>;
					trip = <0x52>;
				};

				wifi_cooling_map2 {
					cooling-device = <0x49 0x0 0x1>;
					trip = <0x53>;
				};
			};

			trips {

				trip-point@0 {
					hysteresis = <0x190>;
					phandle = <0x51>;
					temperature = <0xe290>;
					type = "passive";
				};

				trip-point@1 {
					hysteresis = <0x190>;
					phandle = <0x52>;
					temperature = <0xe484>;
					type = "passive";
				};

				trip-point@2 {
					hysteresis = <0x190>;
					phandle = <0x53>;
					temperature = <0xe678>;
					type = "passive";
				};

				trip-point@3 {
					hysteresis = <0x190>;
					phandle = <0xb3>;
					temperature = <0xea60>;
					type = "critical";
				};
			};
		};

		side_thermal {
			policy = "trip_step_wise";
			polling-delay = <0x3e8>;
			polling-delay-passive = <0x64>;
			sustainable-power = <0x866>;
			thermal-sensors = <0x54>;

			cooling-maps {

				cpucore_cooling_map0 {
					contribution = <0x400>;
					cooling-device = <0x48 0x0 0x0>;
					trip = <0x55>;
				};

				cpucore_cooling_map1 {
					contribution = <0x400>;
					cooling-device = <0x48 0x0 0x0>;
					trip = <0x56>;
				};

				cpucore_cooling_map2 {
					cooling-device = <0x48 0x0 0x1>;
					trip = <0x57>;
				};

				cpufreq_cooling_map0 {
					contribution = <0x400>;
					cooling-device = <0x45 0x0 0x4>;
					trip = <0x55>;
				};

				cpufreq_cooling_map1 {
					contribution = <0x400>;
					cooling-device = <0x45 0x4 0x6>;
					trip = <0x56>;
				};

				cpufreq_cooling_map2 {
					contribution = <0x400>;
					cooling-device = <0x45 0x6 0x8>;
					trip = <0x57>;
				};

				gpufreq_cooling_map0 {
					contribution = <0x400>;
					cooling-device = <0x4a 0x0 0x0>;
					trip = <0x55>;
				};

				gpufreq_cooling_map1 {
					contribution = <0x400>;
					cooling-device = <0x4a 0x0 0x1>;
					trip = <0x56>;
				};

				gpufreq_cooling_map2 {
					contribution = <0x400>;
					cooling-device = <0x4a 0x1 0x3>;
					trip = <0x57>;
				};

				wifi_cooling_map0 {
					contribution = <0x400>;
					cooling-device = <0x49 0x0 0x0>;
					trip = <0x55>;
				};

				wifi_cooling_map1 {
					contribution = <0x400>;
					cooling-device = <0x49 0x0 0x0>;
					trip = <0x56>;
				};

				wifi_cooling_map2 {
					cooling-device = <0x49 0x0 0x1>;
					trip = <0x57>;
				};
			};

			trips {

				trip-point@0 {
					hysteresis = <0x190>;
					phandle = <0x55>;
					temperature = <0xe290>;
					type = "passive";
				};

				trip-point@1 {
					hysteresis = <0x190>;
					phandle = <0x56>;
					temperature = <0xe484>;
					type = "passive";
				};

				trip-point@2 {
					hysteresis = <0x190>;
					phandle = <0x57>;
					temperature = <0xe678>;
					type = "passive";
				};

				trip-point@3 {
					hysteresis = <0x190>;
					phandle = <0xb4>;
					temperature = <0xea60>;
					type = "critical";
				};
			};
		};

		soc_thermal {
			policy = "trip_step_wise";
			polling-delay = <0x3e8>;
			polling-delay-passive = <0x64>;
			sustainable-power = <0x866>;
			thermal-sensors = <0x4b>;

			cooling-maps {

				cpucore_cooling_map0 {
					contribution = <0x400>;
					cooling-device = <0x48 0x0 0x0>;
					trip = <0x4c>;
				};

				cpucore_cooling_map1 {
					contribution = <0x400>;
					cooling-device = <0x48 0x0 0x0>;
					trip = <0x4d>;
				};

				cpucore_cooling_map2 {
					contribution = <0x400>;
					cooling-device = <0x48 0x0 0x1>;
					trip = <0x4e>;
				};

				cpucore_cooling_map3 {
					cooling-device = <0x48 0x1 0x2>;
					trip = <0x4f>;
				};

				cpufreq_cooling_map0 {
					contribution = <0x400>;
					cooling-device = <0x45 0x0 0x2>;
					trip = <0x4c>;
				};

				cpufreq_cooling_map1 {
					contribution = <0x400>;
					cooling-device = <0x45 0x2 0x4>;
					trip = <0x4d>;
				};

				cpufreq_cooling_map2 {
					contribution = <0x400>;
					cooling-device = <0x45 0x4 0x6>;
					trip = <0x4e>;
				};

				cpufreq_cooling_map3 {
					contribution = <0x400>;
					cooling-device = <0x45 0x6 0x8>;
					trip = <0x4f>;
				};

				gpufreq_cooling_map0 {
					contribution = <0x400>;
					cooling-device = <0x4a 0x0 0x0>;
					trip = <0x4c>;
				};

				gpufreq_cooling_map1 {
					contribution = <0x400>;
					cooling-device = <0x4a 0x0 0x1>;
					trip = <0x4d>;
				};

				gpufreq_cooling_map2 {
					contribution = <0x400>;
					cooling-device = <0x4a 0x1 0x3>;
					trip = <0x4e>;
				};

				gpufreq_cooling_map3 {
					contribution = <0x400>;
					cooling-device = <0x4a 0x3 0x3>;
					trip = <0x4f>;
				};

				wifi_cooling_map0 {
					contribution = <0x400>;
					cooling-device = <0x49 0x0 0x0>;
					trip = <0x4c>;
				};

				wifi_cooling_map1 {
					contribution = <0x400>;
					cooling-device = <0x49 0x0 0x0>;
					trip = <0x4d>;
				};

				wifi_cooling_map2 {
					contribution = <0x400>;
					cooling-device = <0x49 0x0 0x1>;
					trip = <0x4e>;
				};

				wifi_cooling_map3 {
					cooling-device = <0x49 0x1 0x2>;
					trip = <0x4f>;
				};
			};

			trips {

				trip-point@0 {
					hysteresis = <0xbb8>;
					phandle = <0x4c>;
					temperature = <0x16378>;
					type = "passive";
				};

				trip-point@1 {
					hysteresis = <0xaf0>;
					phandle = <0x4d>;
					temperature = <0x16f30>;
					type = "passive";
				};

				trip-point@2 {
					hysteresis = <0xdac>;
					phandle = <0x4e>;
					temperature = <0x17ed0>;
					type = "passive";
				};

				trip-point@3 {
					hysteresis = <0xdac>;
					phandle = <0x4f>;
					temperature = <0x18e70>;
					type = "passive";
				};

				trip-point@4 {
					hysteresis = <0xdac>;
					phandle = <0xb2>;
					temperature = <0x1adb0>;
					type = "critical";
				};
			};
		};

		top_thermal {
			policy = "trip_step_wise";
			polling-delay = <0x3e8>;
			polling-delay-passive = <0x64>;
			sustainable-power = <0x866>;
			thermal-sensors = <0x43>;

			cooling-maps {

				cpucore_cooling_map0 {
					contribution = <0x400>;
					cooling-device = <0x48 0x0 0x0>;
					trip = <0x44>;
				};

				cpucore_cooling_map1 {
					contribution = <0x400>;
					cooling-device = <0x48 0x0 0x0>;
					trip = <0x46>;
				};

				cpucore_cooling_map2 {
					cooling-device = <0x48 0x0 0x1>;
					trip = <0x47>;
				};

				cpufreq_cooling_map0 {
					contribution = <0x400>;
					cooling-device = <0x45 0x0 0x4>;
					trip = <0x44>;
				};

				cpufreq_cooling_map1 {
					contribution = <0x400>;
					cooling-device = <0x45 0x4 0x6>;
					trip = <0x46>;
				};

				cpufreq_cooling_map2 {
					contribution = <0x400>;
					cooling-device = <0x45 0x6 0x8>;
					trip = <0x47>;
				};

				gpufreq_cooling_map0 {
					contribution = <0x400>;
					cooling-device = <0x4a 0x0 0x0>;
					trip = <0x44>;
				};

				gpufreq_cooling_map1 {
					contribution = <0x400>;
					cooling-device = <0x4a 0x0 0x1>;
					trip = <0x46>;
				};

				gpufreq_cooling_map2 {
					contribution = <0x400>;
					cooling-device = <0x4a 0x1 0x3>;
					trip = <0x47>;
				};

				wifi_cooling_map0 {
					contribution = <0x400>;
					cooling-device = <0x49 0x0 0x0>;
					trip = <0x44>;
				};

				wifi_cooling_map1 {
					contribution = <0x400>;
					cooling-device = <0x49 0x0 0x0>;
					trip = <0x46>;
				};

				wifi_cooling_map2 {
					cooling-device = <0x49 0x0 0x1>;
					trip = <0x47>;
				};
			};

			trips {

				trip-point@0 {
					hysteresis = <0x190>;
					phandle = <0x44>;
					temperature = <0xe290>;
					type = "passive";
				};

				trip-point@1 {
					hysteresis = <0x190>;
					phandle = <0x46>;
					temperature = <0xe484>;
					type = "passive";
				};

				trip-point@2 {
					hysteresis = <0x190>;
					phandle = <0x47>;
					temperature = <0xe678>;
					type = "passive";
				};

				trip-point@3 {
					hysteresis = <0x190>;
					phandle = <0xb1>;
					temperature = <0xea60>;
					type = "critical";
				};
			};
		};
	};

	thermistor0 {
		adc_channel = <0x0>;
		compatible = "mtk,thermistor";
		device_name = "thermistor0";
		ntc_table = <0x7>;
		over_critical_low = <0x2fc44>;
		phandle = <0xb8>;
		pull_up_resistor = <0x2710>;
		pull_up_voltage = <0x708>;
		status = "okay";
	};

	thermistor1 {
		adc_channel = <0x1>;
		compatible = "mtk,thermistor";
		device_name = "thermistor1";
		ntc_table = <0x7>;
		over_critical_low = <0x2fc44>;
		phandle = <0xb9>;
		pull_up_resistor = <0x2710>;
		pull_up_voltage = <0x708>;
		status = "okay";
	};

	timer {
		compatible = "arm,armv8-timer";
		interrupt-parent = <0x1>;
		interrupts = <0x1 0xd 0x4 0x1 0xe 0x4 0x1 0xb 0x4 0x1 0xa 0x4>;
		phandle = <0x66>;
	};

	virtual-sensor0 {
		#thermal-sensor-cells = <0x0>;
		compatible = "amazon,virtual_sensor";
		phandle = <0x43>;

		cooling_devices {
		};

		vs_components {

			vs_thermistor0 {
				alpha = <0x37f>;
				offset = <0xffff7eb4>;
				vs_name = "thermistor0";
				weight = <0x1b7>;
			};

			vs_thermistor1 {
				alpha = <0x37f>;
				offset = <0x5fb4>;
				vs_name = "thermistor1";
				weight = <0xa1>;
			};
		};
	};

	virtual-sensor1 {
		#thermal-sensor-cells = <0x0>;
		compatible = "amazon,virtual_sensor";
		phandle = <0x50>;

		cooling_devices {
		};

		vs_components {

			vs_thermistor0 {
				alpha = <0x2e8>;
				offset = <0x11eb8>;
				vs_name = "thermistor0";
				weight = <0x37>;
			};

			vs_thermistor1 {
				alpha = <0x197>;
				offset = <0xffffcf90>;
				vs_name = "thermistor1";
				weight = <0x273>;
			};
		};
	};

	virtual-sensor2 {
		#thermal-sensor-cells = <0x0>;
		compatible = "amazon,virtual_sensor";
		phandle = <0x54>;

		cooling_devices {
		};

		vs_components {

			vs_thermistor0 {
				alpha = <0x352>;
				offset = <0xffffa240>;
				vs_name = "thermistor0";
				weight = <0x220>;
			};

			vs_thermistor1 {
				alpha = <0x352>;
				offset = <0xc990>;
				vs_name = "thermistor1";
				weight = <0x54>;
			};
		};
	};
};
